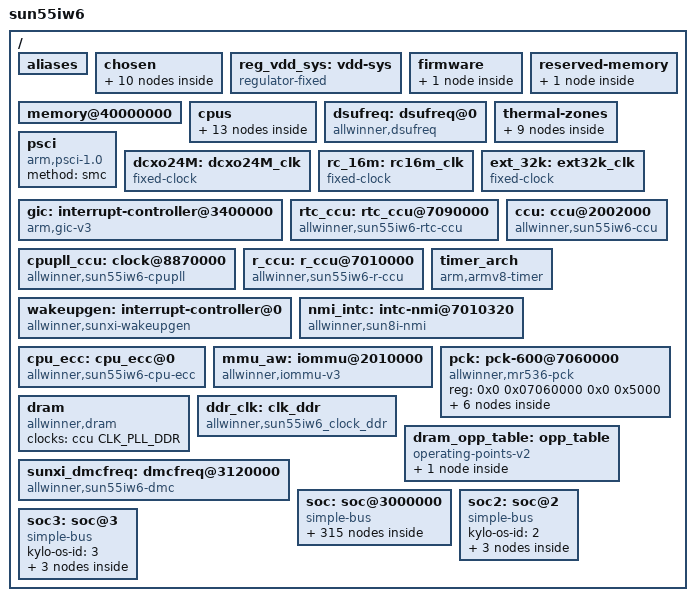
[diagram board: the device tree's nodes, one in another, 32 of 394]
// SPDX-License-Identifier: (GPL-2.0+ or MIT)
#include <dt-bindings/clock/sun55iw6-ccu.h>
#include <dt-bindings/clock/sun55iw6-rtc.h>
#include <dt-bindings/clock/sun55iw6-r-ccu.h>
#include <dt-bindings/gpio/gpio.h>
#include <dt-bindings/gpio/sun4i-gpio.h>
#include <dt-bindings/interrupt-controller/arm-gic.h>
#include <dt-bindings/reset/sun55iw6-ccu.h>
#include <dt-bindings/reset/sun55iw6-r-ccu.h>
#include <dt-bindings/power/mr536-power.h>
#include <dt-bindings/phy/phy.h>
#include <dt-bindings/thermal/thermal.h>
#include <dt-bindings/spi/sunxi-spi.h>
#include <dt-bindings/clock/sun55iw6-cpupll-ccu.h>
#include <dt-bindings/display/sunxi-lcd.h>
#include "sun55iw6p1-cpu-vf.dtsi"

/ {
	model = "sun55iw6";
	interrupt-parent = <&gic>;
	#address-cells = <2>;
	#size-cells = <2>;

	aliases {
		serial0 = &uart0;
		serial1 = &uart1;
		serial2 = &uart2;
		serial3 = &uart3;
		serial4 = &uart4;
		serial5 = &uart5;
		serial6 = &uart6;
		serial7 = &uart7;
		serial8 = &uart8;
		serial9 = &uart9;
		serial10 = &uart10;
		serial11 = &uart11;
		serial12 = &uart12;
		serial13 = &uart13;
		serial14 = &uart14;
		serial15 = &uart15;
		serial16 = &uart16;
		twi0 = &twi0;
		twi1 = &twi1;
		twi2 = &twi2;
		twi3 = &twi3;
		twi4 = &twi4;
		twi5 = &twi5;
		twi6 = &twi6;
		twi7 = &s_twi0;
		twi8 = &s_twi1;
		spi0 = &spi0;
		spi1 = &spi1;
		spi2 = &spi2;
		spi3 = &spi3;
		spi4 = &spi4;
		spi5 = &r_spi0;
		spif0 = &spif0;
		nand0 = &nand0;
		sunxi-mmc0 = &sdc0;
		sunxi-mmc2 = &sdc2;
		ir0 = &irrx0;
		ir1 = &irrx1;
		ir2 = &irrx2;
		ir3 = &irrx3;
		ir4 = &s_irrx;
		gpadc0 = &gpadc0;
		gpadc1 = &gpadc1;
		gpadc2 = &gpadc2;
		gpadc3 = &gpadc3;
		ethernet0 = &gmac0;
		ethernet1 = &gmac1;
		lbc = &lbc;
	};

	chosen {
		linux,initrd-start = <0x0 0x0>;
		linux,initrd-end = <0x0 0x0>;
		#address-cells = <0x2>;
		#size-cells = <0x1>;

		stdout-path = "/soc@3000000/uart@2500000";
		kylo-os-num = <3>;

		hyper {
			compatible = "kylo,kyper";
			reg = <0x0 0x60000000 0x08000000>;
		};

		dom1 {
			compatible = "xen,domain";
			#address-cells = <0x2>;
			#size-cells = <0x1>;
			memory = <0x0 0x140000>;
			xen,static-mem = <0x0 0x80000000 0x40000000>, <0x0 0x40000000 0x10000000>;
			cpu_ids = <&cpu0>,<&cpu1>;
			direct-map;
			kylo-os-type = <0>;  /* 0:linux  1:freeetos */

			module@0 {
				compatible = "multiboot,kernel", "multiboot,module";
				reg = <0x100 0x4008000 0xffffff>;           /* size update by uboot */
				reserve-bootargs;
				bootargs = " a=a ";
			};

			module@1 {
				compatible = "multiboot,ramdisk", "multiboot,module";
				reg = <0x0 0x41000000 0x4fffff>;  /* size update by uboot */
			};
		};

#if 1
		dom2 {
			compatible = "xen,domain";
			#address-cells = <0x2>;
			#size-cells = <0x1>;
			memory = <0x0 0x40000>;
			xen,static-mem = <0x0 0x50000000 0x10000000>;
			cpu_ids = <&cpu2>;
			/* vpl011; */
			direct-map;

			kylo-uart-args = "8,B,4,5,7";  /* uart8, PB4, PB5, 0111*/
			kylo-os-type = <0>;  /* 0:linux  1:freeetos */
			kylo-os-zone-name = "dom2-boot";

			module@0 {
				compatible = "multiboot,kernel", "multiboot,module";
				reg = <0x0 0x90000000 0x4000000>;      /* update by uboot, addr is boot.img base*/
				bootargs = " earlyprintk=sunxi-uart,0x02608000 root=/dev/mmcblk0p5 init=/init console=ttyAS8,115200 clk_ignore_unused";
			};

			module@1 {
				compatible = "multiboot,ramdisk", "multiboot,module";
				reg = <0x0 0x43000000 0xffffff>;       /* update by uboot */
			};

		};
#endif

#if 1
		dom3 {
			compatible = "xen,domain";
			#address-cells = <0x2>;
			#size-cells = <0x1>;
			memory = <0x0 0x40000>;
			xen,static-mem = <0x0 0x70000000 0x10000000>;
			cpu_ids = <&cpu3>;
			direct-map;
			kylo-uart-args = "2,B,0,1,2";  /* uart2, PB0, PB1, 0010*/
			kylo-os-type = <0>;  /* 0:linux  1:freeetos */
			kylo-os-zone-name = "dom2-boot";

			module@0 {
				compatible = "multiboot,kernel", "multiboot,module";
				reg = <0x0 0x98000000 0x4000000>;      /* update by uboot, addr is boot.img base */
				bootargs = " earlyprintk=sunxi-uart,0x02602000 root=/dev/mmcblk0p5 init=/init console=ttyAS2,115200 clk_ignore_unused";
			};

			module@1 {
				compatible = "multiboot,ramdisk", "multiboot,module";
				reg = <0x0 0x43000000 0xffffff>;       /* update by uboot */
			};
		};
#endif
	};


	reg_vdd_sys: vdd-sys {
		compatible = "regulator-fixed";
		regulator-name = "vdd_sys";
		regulator-min-microvolt = <900000>;
		regulator-max-microvolt = <900000>;
		regulator-boot-on;
		regulator-always-on;
	};

	firmware {
		optee {
			compatible = "linaro,optee-tz";
			method = "smc";
		};
	};

	reserved-memory {
		#address-cells = <2>;
		#size-cells = <2>;
		ranges;

		bl31 {
			reg = <0x0 0x48000000 0x0 0x01000000>;
		};
	};

	/* avoid panic when memory-node err(from uboot) */
	memory@40000000 {
		device_type = "memory";
		reg = <0x00000000 0x40000000 0x00000000 0x20000000>;
	};

	cpus {
		#address-cells = <2>;
		#size-cells = <0>;

		cpu0: cpu@0 {
			device_type = "cpu";
			compatible = "arm,cortex-a55";
			reg = <0x0 0x0>;
			enable-method = "psci";
			cpu-idle-states = <&CPU_SLEEP_0 &CLUSTER_SLEEP_0>;
			capacity-dmips-mhz = <1024>;
			clocks = <&cpupll_ccu CLK_PLL_CPU_L0>;
			operating-points-v2 = <&cluster_opp_table>;
			#cooling-cells = <2>;
			dynamic-power-coefficient = <286>;
		};

		cpu1: cpu@100 {
			device_type = "cpu";
			compatible = "arm,cortex-a55";
			reg = <0x0 0x100>;
			enable-method = "psci";
			cpu-idle-states = <&CPU_SLEEP_0 &CLUSTER_SLEEP_0>;
			capacity-dmips-mhz = <1024>;
			clocks = <&cpupll_ccu CLK_PLL_CPU_L0>;
			operating-points-v2 = <&cluster_opp_table>;
			#cooling-cells = <2>;
		};

		cpu2: cpu@200 {
			device_type = "cpu";
			compatible = "arm,cortex-a55";
			reg = <0x0 0x200>;
			enable-method = "psci";
			cpu-idle-states = <&CPU_SLEEP_0 &CLUSTER_SLEEP_0>;
			capacity-dmips-mhz = <1024>;
			clocks = <&cpupll_ccu CLK_PLL_CPU_L0>;
			operating-points-v2 = <&cluster_opp_table>;
			#cooling-cells = <2>;
		};

		cpu3: cpu@300 {
			device_type = "cpu";
			compatible = "arm,cortex-a55";
			reg = <0x0 0x300>;
			enable-method = "psci";
			cpu-idle-states = <&CPU_SLEEP_0 &CLUSTER_SLEEP_0>;
			capacity-dmips-mhz = <1024>;
			clocks = <&cpupll_ccu CLK_PLL_CPU_L0>;
			operating-points-v2 = <&cluster_opp_table>;
			#cooling-cells = <2>;
		};

		cpu-map {
			cluster0 {
				core0 {
					cpu = <&cpu0>;
				};
				core1 {
					cpu = <&cpu1>;
				};
				core2 {
					cpu = <&cpu2>;
				};
				core3 {
					cpu = <&cpu3>;
				};
			};
		};

		idle-states {
			entry-method = "arm,psci";

			CPU_SLEEP_0: cpu-sleep-0 {
				compatible = "arm,idle-state";
				arm,psci-suspend-param = <0x0010000>;
				entry-latency-us = <46>;
				exit-latency-us = <59>;
				min-residency-us = <3570>;
				local-timer-stop;
			};

			CLUSTER_SLEEP_0: cluster-sleep-0 {
				compatible = "arm,idle-state";
				arm,psci-suspend-param = <0x1010000>;
				entry-latency-us = <47>;
				exit-latency-us = <74>;
				min-residency-us = <5000>;
				local-timer-stop;
			};
		};
	};

	dsufreq: dsufreq@0 {
		compatible = "allwinner,dsufreq";
		reg = <0x0 0x08860000 0x0 0x1000>;
		clocks = <&cpupll_ccu CLK_PLL_DSU>;
		operating-points-v2 = <&dsu_opp_table>;
	};

	thermal-zones {
		cpu_thermal_zone: cpu_thermal_zone {
			polling-delay-passive = <100>;
			polling-delay = <1000>;
			thermal-sensors = <&ths 0>;
			sustainable-power = <1200>;

			cpu_trips: trips {
				cpu_threshold: trip-point@0 {
					temperature = <70000>;
					type = "passive";
					hysteresis = <0>;
				};
				cpu_target: trip-point@1 {
					temperature = <90000>;
					type = "passive";
					hysteresis = <0>;
				};
				cpu_crit: cpu_crit@0 {
					temperature = <110000>;
					type = "critical";
					hysteresis = <0>;
				};
			};

			cooling-maps {
				map0 {
					trip = <&cpu_target>;
					cooling-device = <&cpu0
					THERMAL_NO_LIMIT
					THERMAL_NO_LIMIT>;
					contribution = <1024>;
				};
			};
		};

		npu_thermal_zone {
			polling-delay-passive = <100>;
			polling-delay = <1000>;
			thermal-sensors = <&ths 1>;
		};

		ddr_thermal_zone {
			polling-delay-passive = <0>;
			polling-delay = <0>;
			thermal-sensors = <&ths 2>;
		};
	};


	psci {
		compatible = "arm,psci-1.0";
		method = "smc";
	};

	dcxo24M: dcxo24M_clk {
		#clock-cells = <0>;
		compatible = "fixed-clock";
		clock-frequency = <24000000>;
		clock-output-names = "dcxo24M";
		device-sharing;
	};

	rc_16m: rc16m_clk {
		#clock-cells = <0>;
		compatible = "fixed-clock";
		clock-frequency = <16000000>;
		clock-accuracy = <300000000>;
		clock-output-names = "rc-16m";
		device-sharing;
	};

	ext_32k: ext32k_clk {
		#clock-cells = <0>;
		compatible = "fixed-clock";
		clock-frequency = <32768>;
		clock-output-names = "ext-32k";
		device-sharing;
	};

	gic: interrupt-controller@3400000 {
		compatible = "arm,gic-v3";
		#interrupt-cells = <3>;
		#address-cells = <0>;
		ranges;
		interrupts = <GIC_PPI 9 0xf04>;  /* GIC Maintenence IRQ */
		interrupt-controller;
		reg = <0x0 0x03400000 0 0x10000>, /* GIC Dist */
		      <0x0 0x03460000 0 0xFF004>; /* GIC Re */
		interrupt-parent = <&gic>;
		phandle = <65000>;               /* use by hyper must need */
	};

	rtc_ccu: rtc_ccu@7090000 {
		compatible = "allwinner,sun55iw6-rtc-ccu";
		reg = <0x0 0x07090000 0x0 0x328>;
		#clock-cells = <1>;
		#reset-cells = <1>;
		device-sharing;
	};

	cpupll_ccu: clock@8870000 {
		compatible = "allwinner,sun55iw6-cpupll";
		reg = <0x0 0x08870000 0x0 0x78>;
		#clock-cells = <1>;
		#reset-cells = <1>;
		pll_step = <0x8>;
		pll_ssc = <0x3300>;
		device-sharing;
	};

	ccu: ccu@2002000 {
		compatible = "allwinner,sun55iw6-ccu";
		reg = <0x0 0x02002000 0x0 0x2000>;
		clocks = <&dcxo24M>, <&rtc_ccu CLK_OSC32K>, <&rc_16m>;
		clock-names = "hosc", "losc", "iosc";
		#clock-cells = <1>;
		#reset-cells = <1>;
		device-sharing;
	};

	r_ccu: r_ccu@7010000 {
		compatible = "allwinner,sun55iw6-r-ccu";
		reg = <0x0 0x07010000 0x0 0x230>;
		#clock-cells = <1>;
		#reset-cells = <1>;
		device-sharing;
	};

	wakeupgen: interrupt-controller@0 {
		compatible = "allwinner,sunxi-wakeupgen";
		interrupt-controller;
		#interrupt-cells = <3>;
		#address-cells = <0>;
		interrupt-parent = <&gic>;
	};

	timer_arch {
		compatible = "arm,armv8-timer";
		interrupts = <GIC_PPI 13 (GIC_CPU_MASK_SIMPLE(4) | IRQ_TYPE_LEVEL_LOW)>,
			   <GIC_PPI 14 (GIC_CPU_MASK_SIMPLE(4) | IRQ_TYPE_LEVEL_LOW)>,
			   <GIC_PPI 11 (GIC_CPU_MASK_SIMPLE(4) | IRQ_TYPE_LEVEL_LOW)>,
			   <GIC_PPI 10 (GIC_CPU_MASK_SIMPLE(4) | IRQ_TYPE_LEVEL_LOW)>;
		clock-frequency = <24000000>;
		interrupt-parent = <&gic>;
		arm,no-tick-in-suspend;
	};

	nmi_intc: intc-nmi@7010320 {
		compatible = "allwinner,sun8i-nmi";
		interrupt-parent = <&gic>;
		#interrupt-cells = <2>;
		#address-cells = <0>;
		interrupt-controller;
		reg = <0x0 0x07010320 0 0xc>;
		interrupts = <GIC_SPI 192 IRQ_TYPE_LEVEL_HIGH>;
	};

	cpu_ecc: cpu_ecc@0 {
		compatible = "allwinner,sun55iw6-cpu-ecc";
		interrupts = <GIC_SPI 242 IRQ_TYPE_LEVEL_HIGH>,
			<GIC_SPI 243 IRQ_TYPE_LEVEL_HIGH>,
			<GIC_SPI 244 IRQ_TYPE_LEVEL_HIGH>,
			<GIC_SPI 245 IRQ_TYPE_LEVEL_HIGH>,
			<GIC_SPI 246 IRQ_TYPE_LEVEL_HIGH>,
			<GIC_SPI 247 IRQ_TYPE_LEVEL_HIGH>,
			<GIC_SPI 248 IRQ_TYPE_LEVEL_HIGH>,
			<GIC_SPI 249 IRQ_TYPE_LEVEL_HIGH>,
			<GIC_SPI 250 IRQ_TYPE_LEVEL_HIGH>,
			<GIC_SPI 251 IRQ_TYPE_LEVEL_HIGH>;
		interrupt-names = "nerrirq0", "nerrirq1", "nerrirq2", "nerrirq3", "nerrirq4",
				"nfaultirq0", "nfaultirq1", "nfaultirq2", "nfaultirq3", "nfaultirq4";
	};

	mmu_aw: iommu@2010000 {
		compatible = "allwinner,iommu-v3";
		reg = <0x0 0x02010000 0x0 0x1000>;
		interrupts = <GIC_SPI 65 IRQ_TYPE_LEVEL_HIGH>;
		interrupt-names = "iommu-irq";
		clocks = <&ccu CLK_IOMMU>;
		clock-names = "iommu";
		/* clock-frequency = <24000000>; */
		#iommu-cells = <2>;
		version=<0x17>;
		tlb_prefetch = <0x3007f>;
		tlb_invalid_mode = <0x1>;
		ptw_invalid_mode = <0x1>;
		masters = "ISP", "CSI", "VE0", "RESERVED", "G2D",
			"DE", "E907", "DEBUG_MODE";
		valid_masters=<7>;
	};

	pck: pck-600@7060000 {
		compatible = "allwinner,mr536-pck", "syscon", "simple-mfd";
		reg = <0x0 0x07060000 0x0 0x5000>;

		pd: power-controller {
			compatible = "allwinner,mr536-pck-600";
			clocks = <&r_ccu CLK_R_PPU>;
			clock-names = "pck";
			#power-domain-cells = <1>;
			#address-cells = <1>;
			#size-cells = <0>;

			pd1_vi@MR536_PCK_VI {
				reg = <MR536_PCK_VI>;
			};
			pd1_ve@MR536_PCK_VE {
				reg = <MR536_PCK_VE>;
			};
			pd1_npu@MR536_PCK_NPU {
				reg = <MR536_PCK_NPU>;
			};
			pd1_serdes@MR536_PCK_SERDES {
				reg = <MR536_PCK_SERDES>;
			};
			pd1_vo@MR536_PCK_VO {
				reg = <MR536_PCK_VO>;
			};
		};
	};


	dram: dram {
		compatible = "allwinner,dram";
		clocks = <&ccu CLK_PLL_DDR>;
		clock-names = "pll_ddr";
	};

	ddr_clk: clk_ddr {
		compatible = "allwinner,sun55iw6_clock_ddr";
		reg = <0x0 0x02002000 0x0 0x1000>;
		clocks = <&ccu CLK_PLL_DDR>;
		clock-names = "pll_ddr";
		#clock-cells = <0>;
	};

	dram_opp_table: opp_table {
		compatible = "operating-points-v2";
		opp@150000000 {
			opp-hz = /bits/ 64 <150000000>;
			clock-latency-ns = <150000>;
			opp-microvolt = <900000>;
		};
	};

	sunxi_dmcfreq: dmcfreq@3120000 {
		compatible = "allwinner,sun55iw6-dmc", "syscon";
		reg = <0x0 0x03120000 0x0 0x11000>,
			  <0x0 0x02020000 0x0 0x4000>;
		interrupts = <GIC_SPI 121 IRQ_TYPE_LEVEL_HIGH>,
					 <GIC_SPI 229 IRQ_TYPE_LEVEL_HIGH>,
					 <GIC_SPI 233 IRQ_TYPE_LEVEL_HIGH>;
		clocks = <&ddr_clk>, <&ccu CLK_NSI>;
		clock-names = "dram", "bus";
		operating-points-v2 = <&dram_opp_table>;
		upthreshold = <60>;
		downdifferential = <20>;
		vddcore-supply = <&reg_vdd_sys>;
		normalvoltage = <900000>;
		boostvoltage = <900000>;
	};

	soc: soc@3000000 {
		compatible = "simple-bus";
		#address-cells = <2>;
		#size-cells = <2>;
		ranges;


		pio: pinctrl@3604000 {
			//#address-cells = <1>;
			//#size-cells = <0>;
			compatible = "allwinner,sun55iw6-pinctrl";
			reg = <0x0 0x03604000 0x0 0x600>;
			interrupts = <GIC_SPI 67 IRQ_TYPE_LEVEL_HIGH>,
				     <GIC_SPI 69 IRQ_TYPE_LEVEL_HIGH>,
				     <GIC_SPI 71 IRQ_TYPE_LEVEL_HIGH>,
				     <GIC_SPI 73 IRQ_TYPE_LEVEL_HIGH>,
				     <GIC_SPI 75 IRQ_TYPE_LEVEL_HIGH>,
				     <GIC_SPI 77 IRQ_TYPE_LEVEL_HIGH>,
				     <GIC_SPI 79 IRQ_TYPE_LEVEL_HIGH>,
				     <GIC_SPI 81 IRQ_TYPE_LEVEL_HIGH>,
				     <GIC_SPI 83 IRQ_TYPE_LEVEL_HIGH>,
				     <GIC_SPI 85 IRQ_TYPE_LEVEL_HIGH>,
				     <GIC_SPI 140 IRQ_TYPE_LEVEL_HIGH>;
			clocks = <&ccu CLK_APB1>, <&dcxo24M>, <&rtc_ccu CLK_OSC32K>;
			clock-names = "apb", "hosc", "losc";
			gpio-controller;
			#gpio-cells = <3>;
			interrupt-controller;
			#interrupt-cells = <3>;

			/* set appropriate driving strenth, other driving strenth signals are relatively poor, the cfg from shc  */
			sdc0_pins_a: sdc0@0 {
				pins = "PF2";
				function = "sdc0";
				drive-strength = <40>;
				bias-pull-up;
				power-source = <3300>;
			};

			sdc0_pins_b: sdc0@1 {
				pins = "PF2";
				function = "sdc0";
				drive-strength = <40>;
				bias-pull-up;
				power-source = <1800>;
			};

			sdc0_pins_c: sdc0@2 {
				pins = "PF0", "PF1", "PF2",
				"PF3", "PF4", "PF5";
				function = "gpio_in";
				power-source = <3300>;
			};

			/* TODO: add jtag pin */
			sdc0_pins_d: sdc0@3 {
				pins = "PF2", "PF4";
				function = "uart0";
				drive-strength = <10>;
				bias-pull-up;
				power-source = <3300>;
			};

			sdc0_pins_e: sdc0@4 {
				pins = "PF0", "PF1", "PF3",
						"PF5";
				function = "jtag";
				drive-strength = <10>;
				bias-pull-up;
				power-source = <3300>;
			};

			sdc0_pins_f: sdc0@5 {
				pins = "PF0", "PF1",
						"PF3", "PF4", "PF5";
				function = "sdc0";
				drive-strength = <30>;
				bias-pull-up;
				power-source = <3300>;
			};

			sdc0_pins_g: sdc0@6 {
				pins = "PF0", "PF1",
						"PF3", "PF4", "PF5";
				function = "sdc0";
				drive-strength = <30>;
				bias-pull-up;
				power-source = <1800>;
			};

			sdc1_pins_a: sdc1@0 {
				pins = "PG0";
				function = "sdc1";
				drive-strength = <40>;
				bias-pull-up;
			};

			sdc1_pins_b: sdc1@1 {
				pins = "PG0", "PG1", "PG2",
						"PG3", "PG4", "PG5";
				function = "gpio_in";
			};

			sdc1_pins_c: sdc1@2 {
				pins = "PG1", "PG2",
						"PG3", "PG4", "PG5";
				function = "sdc1";
				drive-strength = <20>;
				bias-pull-up;
			};

			sdc2_pins_a: sdc2@0 {
				pins = "PC1", "PC5";
				function = "sdc2";
				drive-strength = <40>;
				bias-pull-up;
			};

			sdc2_pins_b: sdc2@1 {
				pins = "PC0", "PC1", "PC5", "PC6",
						"PC8", "PC9", "PC10", "PC11",
						"PC13", "PC14", "PC15", "PC16";
				function = "gpio_in";
			};

			sdc2_pins_c: sdc2@2 {
				pins = "PC0";
				function = "sdc2";
				drive-strength = <40>;
				bias-pull-down;
			};

			sdc2_pins_d: sdc2@3 {
				pins = "PC6",
						"PC8", "PC9", "PC10", "PC11",
						"PC13", "PC14", "PC15", "PC16";
				function = "sdc2";
				drive-strength = <20>;
				bias-pull-up;
			};

			test_pins_a: test_pins@0 {
				pins = "PB0", "PB1";
				function = "test";
				drive-strength = <10>;
				bias-pull-up;
			};

			test_pins_b: test_pins@1 {
				pins = "PB0", "PB1";
				function = "gpio_in";
			};

			dsi0_4lane_pins_a: dsi0_4lane@0 {
				pins = "PD0", "PD1", "PD2", "PD3", "PD4", "PD5", "PD6", "PD7", "PD8", "PD9";
				function = "dsi";
				drive-strength = <30>;
				bias-disable;
			};

			dsi0_4lane_pins_b: dsi0_4lane@1 {
				pins = "PD0", "PD1", "PD2", "PD3", "PD4", "PD5", "PD6", "PD7", "PD8", "PD9";
				function = "io_disabled";
				bias-disable;
			};

			lvds0_pins_a: lvds0@0 {
				pins = "PD0", "PD1", "PD2", "PD3", "PD4", "PD5", "PD6", "PD7", "PD8", "PD9";
				function = "lvds0";
				drive-strength = <30>;
			};

			lvds0_pins_b: lvds0@1 {
				pins = "PD0", "PD1", "PD2", "PD3", "PD4", "PD5", "PD6", "PD7", "PD8", "PD9";
				function = "gpio_in";
			};

			lvds1_pins_a: lvds1@0 {
				pins = "PD10", "PD11", "PD12", "PD13", "PD14", "PD15", "PD16", "PD17", "PD18", "PD19";
				function = "lvds1";
				drive-strength = <30>;
			};

			lvds1_pins_b: lvds1@1 {
				pins = "PD10", "PD11", "PD12", "PD13", "PD14", "PD15", "PD16", "PD17", "PD18", "PD19";
				function = "gpio_in";
			};

			rgb0_24pins_a: rgb0@0 {
				pins = "PH8", "PH9", "PD0", "PD1", "PD2", "PD3", "PD4", "PD5", "PH10", "PH11", "PD6", "PD7", "PD8", "PD9", \
					"PD10", "PD11", "PH12", "PH13", "PD12", "PD13", "PD14", "PD15", "PD16", "PD17", "PD18", "PD19", \
					"PD20", "PD21";
				function = "lcd";
				drive-strength = <30>;
			};

			rgb0_24pins_b: rgb0@1 {
				pins = "PH8", "PH9", "PD0", "PD1", "PD2", "PD3", "PD4", "PD5", "PH10", "PH11", "PD6", "PD7", "PD8", "PD9", \
					"PD10", "PD11", "PH12", "PH13", "PD12", "PD13", "PD14", "PD15", "PD16", "PD17", "PD18", "PD19", \
					"PD20", "PD21";
				function = "gpio_in";
			};

			csi_mclk0_pins_a: csi_mclk0@0 {
				pins = "PE0";
				function = "mcsi0_mclk";
				drive-strength = <10>;
			};

			csi_mclk0_pins_b: csi_mclk0@1 {
				pins = "PE0";
				function = "gpio_in";
			};

			csi_mclk1_pins_a: csi_mclk1@0 {
				pins = "PE5";
				function = "mcsi1_mclk";
				drive-strength = <10>;
			};

			csi_mclk1_pins_b: csi_mclk1@1 {
				pins = "PE5";
				function = "gpio_in";
			};

			csi_mclk2_pins_a: csi_mclk2@0 {
				pins = "PE15";
				function = "mcsi2_mclk";
				drive-strength = <10>;
			};

			csi_mclk2_pins_b: csi_mclk2@1 {
				pins = "PE15";
				function = "gpio_in";
			};

			csi_mclk3_pins_a: csi_mclk3@0 {
				pins = "PE10";
				function = "mcsi3_mclk";
				drive-strength = <10>;
			};

			csi_mclk3_pins_b: csi_mclk3@1 {
				pins = "PE10";
				function = "gpio_in";
			};

			ncsi_bt656_pins_a: ncsi_BT656@0 {
				pins = "PK20", "PK22", "PK23",
				"PK4", "PK5", "PK6", "PK7",
				"PK8", "PK9", "PK10", "PK11";
				function = "ncsi";
				drive-strength = <10>;
			};

			ncsi_bt656_pins_b: ncsi_BT656@1 {
				pins = "PK20", "PK22", "PK23",
				"PK4", "PK5", "PK6", "PK7",
				"PK8", "PK9", "PK10", "PK11";
				function = "gpio_in";
			};

			ncsi_bt1120_pins_a: ncsi_BT1120@0 {
				pins = "PK20", "PK22", "PK23",
				"PK4", "PK5", "PK6", "PK7",
				"PK8", "PK9", "PK10", "PK11",
				"PK12", "PK13", "PK14", "PK15",
				"PK16", "PK17", "PK18", "PK19";
				function = "ncsi";
				drive-strength = <10>;
			};

			ncsi_bt1120_pins_b: ncsi_BT1120@1 {
				pins = "PK20", "PK22", "PK23",
				"PK4", "PK5", "PK6", "PK7",
				"PK8", "PK9", "PK10", "PK11",
				"PK12", "PK13", "PK14", "PK15",
				"PK16", "PK17", "PK18", "PK19";
				function = "gpio_in";
			};

			mipia_pins_a: mipia@0 {
				pins = "PK0", "PK1", "PK2",
					"PK3", "PK4", "PK5";
				function = "mcsia";
				drive-strength = <10>;

			};

			mipia_pins_b: mipia@1 {
				pins = "PK0", "PK1", "PK2",
					"PK3", "PK4", "PK5";
				function = "gpio_in";
			};

			mipib_pins_a: mipib@0 {
				pins = "PK6", "PK7", "PK8",
					"PK9", "PK10", "PK11";
				function = "mcsib";
				drive-strength = <10>;
			};

			mipib_pins_b: mipib@1 {
				pins = "PK6", "PK7", "PK8",
					"PK9", "PK10", "PK11";
				function = "gpio_in";

			};

			mipib_4lane_pins_a: mipib_4lane@0 {
				pins = "PK6", "PK7", "PK8",
					"PK9", "PK10", "PK11";
				function = "mcsib";
				drive-strength = <10>;
			};

			mipib_4lane_pins_b: mipib_4lane@1 {
				pins = "PK6", "PK7", "PK8",
					"PK9", "PK10", "PK11";
				function = "gpio_in";
			};

			mipic_pins_a: mipic@0 {
				pins = "PK12", "PK13", "PK14",
					"PK15", "PK16", "PK17";
				function = "mcsic";
				drive-strength = <10>;

			};

			mipic_pins_b: mipic@1 {
				pins = "PK12", "PK13", "PK14",
					"PK15", "PK16", "PK17";
				function = "gpio_in";
			};

			mipid_pins_a: mipid@0 {
				pins = "PK18", "PK19", "PK20",
					"PK21", "PK22", "PK23";
				function = "mcsid";
				drive-strength = <10>;
			};

			mipid_pins_b: mipid@1 {
				pins = "PK18", "PK19", "PK20",
					"PK21", "PK22", "PK23";
				function = "gpio_in";

			};

			mipid_4lane_pins_a: mipid_4lane@0 {
				pins = "PK18", "PK19", "PK20",
					"PK21", "PK22", "PK23";
				function = "mcsid";
				drive-strength = <10>;
			};

			mipid_4lane_pins_b: mipid_4lane@1 {
				pins = "PK18", "PK19", "PK20",
					"PK21", "PK22", "PK23";
				function = "gpio_in";
			};
		};

		r_pio: pinctrl@7096000 {
			#address-cells = <1>;
			compatible = "allwinner,sun55iw6-r-pinctrl";
			reg = <0x0 0x07096000 0x0 0x800>;
			interrupts = <GIC_SPI 202 IRQ_TYPE_LEVEL_HIGH>, /* GPIOL */
				     <GIC_SPI 204 IRQ_TYPE_LEVEL_HIGH>;     /* GPIOM */
			clocks = <&ccu CLK_R_APBS1>, <&dcxo24M>, <&rtc_ccu CLK_OSC32K>;
			clock-names = "apb", "hosc", "losc";
			gpio-controller;
			#gpio-cells = <3>;
			interrupt-controller;
			#interrupt-cells = <3>;
		};

		pinctrl_test: pinctrl_test@2000000 {
		      reg = <0x0 0x0 0x0 0x0>;
		      compatible = "allwinner,sunxi-pinctrl-test";
		      device_type = "pinctrl-test";
		      pinctrl-0 = <&test_pins_a>;
		      pinctrl-1 = <&test_pins_b>;
		      pinctrl-names = "default", "sleep";
		      test-gpios = <&pio PB 4 GPIO_ACTIVE_LOW>;
		      suspend-gpios = <&pio PB 5 GPIO_ACTIVE_LOW>;
		      wakeup-source;
		      interrupt-parent = <&pio>;
		      interrupts = <PB 6 IRQ_TYPE_LEVEL_HIGH>;
		};

		ths: ths@2086000 {
			compatible = "allwinner,sun55iw6p1-ths";
			reg = <0x0 0x02086000 0x0 0x400>;
			clocks = <&ccu CLK_THS>,<&ccu CLK_GPADC2>;
			clock-names = "bus","gpadc";
			resets = <&ccu RST_BUS_TH>;
			#thermal-sensor-cells = <1>;
		};

		soc_timer0: timer@3008000 {
			compatible = "allwinner,hstimer-v100";
			device_type = "soc_timer";
			reg = <0x0 0x03008000 0x0 0x400>;
			interrupt-parent = <&gic>;
			interrupts = <GIC_SPI 55 IRQ_TYPE_LEVEL_HIGH>;
			clock-names = "parent", "bus", "timer0-mod", "timer1-mod";
			clocks = <&dcxo24M>, <&ccu CLK_BUS_TIMER>, <&ccu CLK_TIMER0>, <&ccu CLK_TIMER1>;
			resets = <&ccu RST_BUS_TIME>;
		};

		arm_pmu {
			compatible = "arm,armv8-pmuv3";
			interrupt-parent = <&gic>;
			interrupts = <GIC_PPI 7 IRQ_TYPE_LEVEL_HIGH>;
		};

		cryptoengine: ce@3040000 {
			compatible = "allwinner,sunxi-ce";
			device_name = "ce";
			reg = <0x0 0x03040000 0x0 0x800>, /* non-secure space */
				<0x0 0x03040800 0x0 0x800>; /* secure space */
			interrupts = <GIC_SPI 52 IRQ_TYPE_EDGE_RISING>, /*non-secure*/
				<GIC_SPI 53 IRQ_TYPE_EDGE_RISING>; /* secure*/
			clock-frequency = <400000000>; /* 400MHz */
			clocks = <&ccu CLK_BUS_CE>, <&ccu CLK_CE>, <&ccu CLK_MBUS_CE_GATE>,
				 <&ccu CLK_PLL_PERI0_400M>, <&ccu CLK_CE_SYS>;
			clock-names = "bus_ce", "ce_clk", "mbus_ce", "clk_src", "ce_sys_clk";
			resets = <&ccu RST_BUS_CE>;
			status = "disabled";
		};

		rtc: rtc@7090000 {
			compatible = "allwinner,rtc-v201";
			device_type = "rtc";
			wakeup-source;
			reg = <0x0 0x07090000 0x0 0x320>;
			interrupts = <GIC_SPI 200 IRQ_TYPE_LEVEL_HIGH>;
			clocks = <&r_ccu CLK_RTC>, <&rtc_ccu CLK_RTC_1K>, <&rtc_ccu CLK_RTC_SPI>;
			clock-names = "r-ahb-rtc", "rtc-1k", "rtc-spi";
			resets = <&r_ccu RST_BUS_RTC>;
			gpr_cur_pos = <6>;
			gpr_bootcount_pos = <7>;
		};

		dump_reg: dump_reg@40000 {
			compatible = "allwinner,sunxi-dump-reg";
			reg = <0x0 0x00040000 0x0 0x0004>;
		};

		wdt: watchdog@2050000 {
			compatible = "allwinner,wdt-v103";
			reg = <0x0 0x02050000 0x0 0x20>;
			interrupts = <GIC_SPI 63 IRQ_TYPE_LEVEL_HIGH>;
		};

		uart0: uart@2600000 {
			compatible = "allwinner,uart-v100";
			reg = <0x0 0x02600000 0x0 0x400>;
			interrupts = <GIC_SPI 2 IRQ_TYPE_LEVEL_HIGH>;
			sunxi,uart-fifosize = <64>;
			clocks = <&ccu CLK_BUS_UART0>;
			resets = <&ccu RST_BUS_UART0>;
			uart0_port = <0>;
			uart0_type = <2>;
			status = "disabled";
		};

		uart1: uart@2601000 {
			compatible = "allwinner,uart-v100";
			device_type = "uart1";
			reg = <0x0 0x02601000 0x0 0x400>;
			interrupts = <GIC_SPI 3 IRQ_TYPE_LEVEL_HIGH>;
			sunxi,uart-fifosize = <128>;
			clocks = <&ccu CLK_BUS_UART1>;
			resets = <&ccu RST_BUS_UART1>;
			uart1_port = <1>;
			uart1_type = <4>;
			//dmas = <&dma0 15>,<&dma0 15>;
			//dma-names = "tx","rx";
			status = "disabled";
		};


		uart3: uart@2603000 {
			compatible = "allwinner,uart-v100";
			device_type = "uart3";
			reg = <0x0 0x02603000 0x0 0x400>;
			interrupts = <GIC_SPI 5 IRQ_TYPE_LEVEL_HIGH>;
			sunxi,uart-fifosize = <128>;
			clocks = <&ccu CLK_BUS_UART3>;
			resets = <&ccu RST_BUS_UART3>;
			uart3_port = <3>;
			uart3_type = <4>;
			//dmas = <&dma0 17>,<&dma0 17>;
			//dma-names = "tx","rx";
			status = "disabled";
		};

		uart4: uart@2604000 {
			compatible = "allwinner,uart-v100";
			device_type = "uart4";
			reg = <0x0 0x02604000 0x0 0x400>;
			interrupts = <GIC_SPI 6 IRQ_TYPE_LEVEL_HIGH>;
			sunxi,uart-fifosize = <128>;
			clocks = <&ccu CLK_BUS_UART4>;
			resets = <&ccu RST_BUS_UART4>;
			uart4_port = <4>;
			uart4_type = <4>;
			//dmas = <&dma0 18>,<&dma0 18>;
			//dma-names = "tx","rx";
			status = "disabled";
		};

		uart5: uart@2605000 {
			compatible = "allwinner,uart-v100";
			device_type = "uart5";
			reg = <0x0 0x02605000 0x0 0x400>;
			interrupts = <GIC_SPI 7 IRQ_TYPE_LEVEL_HIGH>;
			sunxi,uart-fifosize = <128>;
			clocks = <&ccu CLK_BUS_UART5>;
			resets = <&ccu RST_BUS_UART5>;
			uart5_port = <5>;
			uart5_type = <4>;
			//dmas = <&dma0 19>,<&dma0 19>;
			//dma-names = "tx","rx";
			status = "disabled";
		};

		uart6: uart@2606000 {
			compatible = "allwinner,uart-v100";
			device_type = "uart6";
			reg = <0x0 0x02606000 0x0 0x400>;
			interrupts = <GIC_SPI 8 IRQ_TYPE_LEVEL_HIGH>;
			sunxi,uart-fifosize = <128>;
			clocks = <&ccu CLK_BUS_UART6>;
			resets = <&ccu RST_BUS_UART6>;
			uart6_port = <6>;
			uart6_type = <4>;
			//dmas = <&dma0 20>,<&dma0 20>;
			//dma-names = "tx","rx";
			status = "disabled";
		};

		uart7: uart@2607000 {
			compatible = "allwinner,uart-v100";
			device_type = "uart7";
			reg = <0x0 0x02607000 0x0 0x400>;
			interrupts = <GIC_SPI 9 IRQ_TYPE_LEVEL_HIGH>;
			sunxi,uart-fifosize = <128>;
			clocks = <&ccu CLK_BUS_UART7>;
			resets = <&ccu RST_BUS_UART7>;
			uart7_port = <7>;
			uart7_type = <4>;
			//dmas = <&dma0 21>,<&dma0 21>;
			//dma-names = "tx","rx";
			status = "disabled";
		};

		uart9: uart@2609000 {
			compatible = "allwinner,uart-v100";
			device_type = "uart9";
			reg = <0x0 0x02609000 0x0 0x400>;
			interrupts = <GIC_SPI 149 IRQ_TYPE_LEVEL_HIGH>;
			sunxi,uart-fifosize = <64>;
			clocks = <&ccu CLK_BUS_UART9>;
			resets = <&ccu RST_BUS_UART9>;
			uart9_port = <9>;
			uart9_type = <4>;
			//dmas = <&dma0 56>,<&dma0 56>;
			//dma-names = "tx","rx";
			status = "disabled";
		};

		uart10: uart@260a000 {
			compatible = "allwinner,uart-v100";
			device_type = "uart10";
			reg = <0x0 0x0260a000 0x0 0x400>;
			interrupts = <GIC_SPI 150 IRQ_TYPE_LEVEL_HIGH>;
			sunxi,uart-fifosize = <64>;
			clocks = <&ccu CLK_BUS_UART10>;
			resets = <&ccu RST_BUS_UART10>;
			uart10_port = <10>;
			uart10_type = <4>;
			//dmas = <&dma0 57>,<&dma0 57>;
			//dma-names = "tx","rx";
			status = "disabled";
		};

		uart11: uart@260b000 {
			compatible = "allwinner,uart-v100";
			device_type = "uart11";
			reg = <0x0 0x0260b000 0x0 0x400>;
			interrupts = <GIC_SPI 151 IRQ_TYPE_LEVEL_HIGH>;
			sunxi,uart-fifosize = <64>;
			clocks = <&ccu CLK_BUS_UART11>;
			resets = <&ccu RST_BUS_UART11>;
			uart11_port = <11>;
			uart11_type = <4>;
			//dmas = <&dma0 58>,<&dma0 58>;
			//dma-names = "tx","rx";
			status = "disabled";
		};

		uart12: uart@260c000 {
			compatible = "allwinner,uart-v100";
			device_type = "uart12";
			reg = <0x0 0x0260c000 0x0 0x400>;
			interrupts = <GIC_SPI 152 IRQ_TYPE_LEVEL_HIGH>;
			sunxi,uart-fifosize = <64>;
			clocks = <&ccu CLK_BUS_UART12>;
			resets = <&ccu RST_BUS_UART12>;
			uart12_port = <12>;
			uart12_type = <4>;
			//dmas = <&dma0 59>,<&dma0 59>;
			//dma-names = "tx","rx";
			status = "disabled";
		};

		uart13: uart@260d000 {
			compatible = "allwinner,uart-v100";
			device_type = "uart13";
			reg = <0x0 0x0260d000 0x0 0x400>;
			interrupts = <GIC_SPI 153 IRQ_TYPE_LEVEL_HIGH>;
			sunxi,uart-fifosize = <64>;
			clocks = <&ccu CLK_BUS_UART13>;
			resets = <&ccu RST_BUS_UART13>;
			uart13_port = <13>;
			uart13_type = <4>;
			//dmas = <&dma0 60>,<&dma0 60>;
			//dma-names = "tx","rx";
			status = "disabled";
		};

		uart14: uart@260e000 {
			compatible = "allwinner,uart-v100";
			device_type = "uart14";
			reg = <0x0 0x0260e000 0x0 0x400>;
			interrupts = <GIC_SPI 154 IRQ_TYPE_LEVEL_HIGH>;
			sunxi,uart-fifosize = <64>;
			clocks = <&ccu CLK_BUS_UART14>;
			resets = <&ccu RST_BUS_UART14>;
			uart14_port = <14>;
			uart14_type = <4>;
			//dmas = <&dma0 61>,<&dma0 61>;
			//dma-names = "tx","rx";
			status = "disabled";
		};

		uart15: uart@7080000{
			compatible = "allwinner,uart-v100";
			device_type = "uart15";
			reg = <0x0 0x07080000 0x0 0x400>;
			interrupts = <GIC_SPI 205 IRQ_TYPE_LEVEL_HIGH>;
			sunxi,uart-fifosize = <64>;
			clocks = <&r_ccu CLK_R_UART0>;
			resets = <&r_ccu RST_BUS_R_UART0>;
			uart15_port = <15>;
			uart15_type = <4>;
			//dmas = <&dma0 51>,<&dma0 51>;
			//dma-names = "tx","rx";
			status = "disabled";
		};

		uart16: uart@7081000{
			compatible = "allwinner,uart-v100";
			device_type = "uart16";
			reg = <0x0 0x07081000 0x0 0x400>;
			interrupts = <GIC_SPI 206 IRQ_TYPE_LEVEL_HIGH>;
			sunxi,uart-fifosize = <128>;
			clocks = <&r_ccu CLK_R_UART1>;
			resets = <&r_ccu RST_BUS_R_UART1>;
			uart16_port = <16>;
			uart16_type = <4>;
			//dmas = <&dma0 52>,<&dma0 52>;
			//dma-names = "tx","rx";
			status = "disabled";
		};

		rtp: rtp@208c000 {
			compatible = "allwinner,sunxi-rtp-v101";
			reg = <0x0 0x0208c000 0x0 0x400>;
			clocks = <&ccu CLK_TPADC>, <&ccu CLK_TPADC_24M>;
			clock-names = "mod", "bus";
			clock-frequency = <1000000>;
			resets = <&ccu RST_BUS_TPADC>;
			interrupts = <GIC_SPI 159 IRQ_TYPE_LEVEL_HIGH>;
			status = "disabled";
		};

		sdc2: sdmmc@4022000 {
			compatible = "allwinner,sunxi-mmc-v4p6x";
			device_type = "sdc2";
			reg = <0x0 0x04022000 0x0 0x1000>;
			interrupts = <GIC_SPI 42 IRQ_TYPE_LEVEL_HIGH>;
			clocks = <&dcxo24M>,
					<&ccu CLK_PLL_PERI1_800M>,
					<&ccu CLK_PLL_PERI1_600M>,
					<&ccu CLK_SMHC2>,
					<&ccu CLK_BUS_SMHC2>;
			clock-names = "osc24m","pll_periph","pll_periph_2","mmc","ahb";
			resets = <&ccu RST_BUS_SMHC2>;
			reset-names = "rst";
			pinctrl-names = "default","sleep";
			pinctrl-0 = <&sdc2_pins_a &sdc2_pins_c &sdc2_pins_d>;
			pinctrl-1 = <&sdc2_pins_b>;
			bus-width = <8>;
			req-page-count = <2>;
			cap-mmc-highspeed;
			cap-cmd23;
			mmc-cache-ctrl;
			non-removable;
			/*max-frequency = <200000000>;*/
			max-frequency = <50000000>;
			cap-erase;
			mmc-high-capacity-erase-size;
			no-sdio;
			no-sd;
			/*-- speed mode --*/
			/*sm0: DS26_SDR12*/
			/*sm1: HSSDR52_SDR25*/
			/*sm2: HSDDR52_DDR50*/
			/*sm3: HS200_SDR104*/
			/*sm4: HS400*/
			/*-- frequency point --*/
			/*f0: CLK_400K*/
			/*f1: CLK_25M*/
			/*f2: CLK_50M*/
			/*f3: CLK_100M*/
			/*f4: CLK_150M*/
			/*f5: CLK_200M*/
			ctl-spec-caps = <0x328>;
			sdc_tm4_sm0_freq0 = <0>;
			sdc_tm4_sm0_freq1 = <0>;
			sdc_tm4_sm1_freq0 = <0x00000000>;
			sdc_tm4_sm1_freq1 = <0>;
			sdc_tm4_sm2_freq0 = <0x00000000>;
			sdc_tm4_sm2_freq1 = <0>;
			sdc_tm4_sm3_freq0 = <0x05000000>;
			sdc_tm4_sm3_freq1 = <0x00000005>;
			sdc_tm4_sm4_freq0 = <0x00050000>;
			sdc_tm4_sm4_freq1 = <0x00000004>;
			sdc_tm4_sm4_freq0_cmd = <0>;
			sdc_tm4_sm4_freq1_cmd = <0>;

			/*vmmc-supply = <&reg_3p3v>;*/
			/*vqmc-supply = <&reg_3p3v>;*/
			/*vdmc-supply = <&reg_3p3v>;*/
			/*vmmc = "vcc-card";*/
			/*vqmc = "";*/
			/*vdmc = "";*/
			/*sunxi-power-save-mode;*/
			status = "disabled";
		};

		irrx0: irrx@2081000 {
			compatible = "allwinner,irrx";
			reg = <0x0 0x02081000 0x0 0x400>;
			interrupts = <GIC_SPI 27 IRQ_TYPE_LEVEL_HIGH>;
			clocks = <&ccu CLK_BUS_IRRX0>, <&dcxo24M>, <&ccu CLK_IRRX0>;
			clock-names = "bus", "pclk", "mclk";
			resets = <&ccu RST_BUS_IRRX0>;
			status = "disabled";
		};

		irrx1: irrx@2082000 {
			compatible = "allwinner,irrx";
			reg = <0x0 0x02082000 0x0 0x400>;
			interrupts = <GIC_SPI 117 IRQ_TYPE_LEVEL_HIGH>;
			clocks = <&ccu CLK_BUS_IRRX1>, <&dcxo24M>, <&ccu CLK_IRRX1>;
			clock-names = "bus", "pclk", "mclk";
			resets = <&ccu RST_BUS_IRRX1>;
			status = "disabled";
		};

		irrx2: irrx@2083000 {
			compatible = "allwinner,irrx";
			reg = <0x0 0x02083000 0x0 0x400>;
			interrupts = <GIC_SPI 118 IRQ_TYPE_LEVEL_HIGH>;
			clocks = <&ccu CLK_BUS_IRRX2>, <&dcxo24M>, <&ccu CLK_IRRX2>;
			clock-names = "bus", "pclk", "mclk";
			resets = <&ccu RST_BUS_IRRX2>;
			status = "disabled";
		};

		irrx3: irrx@2084000 {
			compatible = "allwinner,irrx";
			reg = <0x0 0x02084000 0x0 0x400>;
			interrupts = <GIC_SPI 119 IRQ_TYPE_LEVEL_HIGH>;
			clocks = <&ccu CLK_BUS_IRRX3>, <&dcxo24M>, <&ccu CLK_IRRX3>;
			clock-names = "bus", "pclk", "mclk";
			resets = <&ccu RST_BUS_IRRX3>;
			status = "disabled";
		};

		s_irrx: irrx@7040000 {
			compatible = "allwinner,irrx";
			reg = <0x0 0x07040000 0x0 0x400>;
			interrupts = <GIC_SPI 210 IRQ_TYPE_LEVEL_HIGH>;
			clocks = <&r_ccu CLK_R_BUS_IRRX>, <&dcxo24M>, <&r_ccu CLK_R_IRRX>;
			clock-names = "bus", "pclk", "mclk";
			resets = <&r_ccu RST_BUS_R_IRRX>;
			status = "disabled";
		};

		irtx0: irtx@2080000 {
			compatible = "allwinner,irtx";
			reg = <0x0 0x02080000 0x0 0x400>;
			interrupts = <GIC_SPI 26 IRQ_TYPE_LEVEL_HIGH>;
			clocks = <&ccu CLK_BUS_IRTX>, <&dcxo24M>, <&ccu CLK_IRTX>;
			clock-names = "bus", "pclk", "mclk";
			resets = <&ccu RST_BUS_IRTX>;
			status = "disabled";
		};

		ledc: ledc@2085000 {
			#address-cells = <1>;
			#size-cells = <0>;
			compatible = "allwinner,sunxi-leds";
			reg = <0x0 0x02085000 0x0 0x400>;
			interrupts = <GIC_SPI 28 IRQ_TYPE_LEVEL_HIGH>;
			clocks = <&ccu CLK_LEDC>, <&ccu CLK_BUS_LEDC>;
			clock-names = "clk_ledc", "clk_cpuapb";
			resets = <&ccu RST_BUS_LEDC>;
			reset-names = "ledc_reset";
			dmas = <&dma0 42>;
			dma-names = "tx";
			status = "disabled";
		};

		lradc: lradc@208b000 {
			compatible = "allwinner,keyboard_1350mv";
			reg = <0x0 0x0208b000 0x0 0x400>;
			interrupts = <GIC_SPI 66 IRQ_TYPE_LEVEL_HIGH>;
			clocks = <&ccu CLK_LRADC>;
			resets = <&ccu RST_BUS_LRADC>;
			status = "disabled";
		};

		npu: npu@1900000 {
			compatible = "allwinner,npu";
			reg = <0x0 0x01900000 0x0 0x1000>;
			device_type = "npu";
			dev_name = "npu";
			interrupts = <GIC_SPI 116 IRQ_TYPE_LEVEL_HIGH>;
			interrupt-names = "npu";
			clocks = <&ccu CLK_NPU>, <&ccu CLK_PLL_NPU_4X>, <&ccu CLK_NPU_TZMA>, <&ccu CLK_BUS_NPU>;
			clock-names = "clk_npu", "clk_parent", "clk_tzma", "clk_bus";
			operating-points-v2 = <&npu_opp_table>;
			resets = <&ccu RST_BUS_NPU_CORE>, <&ccu RST_BUS_NPU_AXI>, <&ccu RST_BUS_NPU_AHB>;
			reset-names = "npu_rst", "npu_axi_rst", "npu_ahb_rst";
			/*
			 * power-domains = <&pd Ti533_PD_NPU>;
			 */
			npu-vf = <696>;
			npu-regulator = <1>;
			status = "disabled";
		};

		sunxi_drm: sunxi-drm {
			compatible = "allwinner,sunxi-drm";
			status = "disabled";
		};

		de: de@5000000 {
			compatible = "allwinner,display-engine-v210";
			iommus = <&mmu_aw 5 1>;
			power-domains = <&pd MR536_PCK_VO>;
			reg = <0x0 0x5000000 0x0 0x400000>;
			interrupts = <GIC_SPI 87 IRQ_TYPE_LEVEL_HIGH>;
			clocks = <&ccu CLK_DE>,
				 <&ccu CLK_DE0>,
				 <&ccu CLK_AHB_VID_OUT_GATE>,
				 <&ccu CLK_MBUS_VO_SYS_GATE>;
			clock-names = "clk_de",
				      "clk_bus_de",
				      "ahb_vid_out",
				      "mbus_vo_sys";
			resets = <&ccu RST_BUS_DE0>;
			reset-names = "rst_bus_de";
			assigned-clocks = <&ccu CLK_DE>;
			assigned-clock-parents = <&ccu CLK_PLL_PERI0_600M>;
			assigned-clock-rates = <300000000>;
			status = "disabled";
			ports {
				disp0: port@0 {
					disp0_out_tcon0: endpoint@0 {
						remote-endpoint = <&tcon0_in_disp0>;
					};
				};
			};
		};

		vo0: vo0@5500000 {
			compatible = "allwinner,tcon-top0";
			reg = <0x0 0x05500000 0x0 0xfff>;
			power-domains = <&pd MR536_PCK_VO>;
			clocks = <&ccu CLK_DPSS>;
			clock-names = "clk_bus_dpss_top";
			resets = <&ccu RST_BUS_DP>,
				 <&ccu RST_BUS_VIDEO_OUT0>;
			reset-names = "rst_bus_dpss_top",
				      "rst_bus_reg";
			status = "disabled";
		};

		lcd0: tcon0@5501000 {
			compatible = "allwinner,tcon-lcd";
			reg = <0x0 0x05501000 0x0 0x1000>;
			interrupts = <GIC_SPI 90 IRQ_TYPE_LEVEL_HIGH>;
			clocks = <&ccu CLK_VO0_TCONLCD0>,
				<&ccu CLK_BUS_VO0_TCONLCD0>,
				 <&ccu CLK_AHB_VID_OUT_GATE>,
				 <&ccu CLK_MBUS_VO_SYS_GATE>;
			clock-names = "clk_tcon",
					"clk_bus_tcon",
					"ahb_vid_out",
					"mbus_vo_sys";
			assigned-clocks = <&ccu CLK_VO0_TCONLCD0>;
			assigned-clock-parents = <&ccu CLK_PLL_VIDEO0_4X>;
			resets = <&ccu RST_BUS_VO0_TCONLCD0>;
			reset-names = "rst_bus_tcon";
			top = <&vo0>;
			status = "disabled";
			ports {
				#address-cells = <1>;
				#size-cells = <0>;
				tcon0_in: port@0 {
					reg = <0>;
					tcon0_in_disp0: endpoint@0 {
						remote-endpoint = <&disp0_out_tcon0>;
					};
				};
				tcon0_out: port@1 {
					#address-cells = <1>;
					#size-cells = <0>;
					reg = <1>;
					tcon0_out_lvds0: endpoint@0 {
						reg = <0>;
						remote-endpoint = <&lvds0_in_tcon0>;
					};
					tcon0_out_dsi0: endpoint@1 {
						reg = <1>;
						remote-endpoint = <&dsi0_in_tcon0>;
					};
					tcon0_out_rgb0: endpoint@2 {
						reg = <2>;
						remote-endpoint = <&rgb0_in_tcon0>;
					};
				};
			};
		};

		dsi0: dsi0@5506000 {
			compatible = "allwinner,dsi0";
			reg = <0x0 0x05506000 0x0 0xfff>;
			interrupts = <GIC_SPI 91 IRQ_TYPE_LEVEL_HIGH>;
			clocks = <&ccu CLK_DSI0>,
				<&ccu CLK_BUS_DSI0>,
				<&dsi0combophy CLK_DSI_HS>,
				<&dsi0combophy CLK_DSI_LS>;
			clock-names = "dsi_clk",
					"dsi_gating_clk",
					"displl_hs",
					"displl_ls";
			assigned-clocks = <&ccu CLK_DSI0>,
					<&ccu CLK_VO0_COMBPHY0>;
			assigned-clock-parents = <&ccu CLK_PLL_PERI0_150M>,
						<&ccu CLK_PLL_VIDEO0_4X>;
			resets = <&ccu RST_BUS_DSI0>;
			reset-names = "dsi_rst_clk";
			phys = <&dsi0combophy>;
			phy-names = "combophy";
			#address-cells = <1>;
			#size-cells = <0>;
			status = "disabled";

			ports {
				dsi0_in: port@0 {
					dsi0_in_tcon0: endpoint@0 {
						remote-endpoint = <&tcon0_out_dsi0>;
					};
				};
			};
		};

		dsi0combophy: phy@5507000 {
			compatible = "allwinner,sunxi-dsi-combo-phy0";
			reg = <0x0 0x05507000 0x0 0x1ff>;
			clocks = <&ccu CLK_BUS_DSI0>;
			clock-names = "phy_gating_clk";
			resets = <&ccu RST_BUS_DSI0>;
			reset-names = "phy_rst_clk";
			#clock-cells = <1>;
			#phy-cells = <0>;
			status = "disabled";
		};

		rgb0: rgb0@1000 {
			compatible = "allwinner,rgb0";
			clocks = <&dsi0combophy CLK_LVDS_OR_RGB>;
			clock-names = "rgb_pclk";
			status = "disabled";
			phys = <&dsi0combophy>;
			phy-names = "combophy0";
			ports {
				#address-cells = <1>;
				#size-cells = <0>;
				rgb0_in: port@0 {
					reg = <0>;
					rgb0_in_tcon0: endpoint@0 {
						remote-endpoint = <&tcon0_out_rgb0>;
					};
				};
				rgb0_out: port@1 {
					reg = <1>;
					rgb0_panel_out: endpoint@0 {
					//	remote-endpoint = <&rgb0_panel_in>>;
					};
				};

			};
		};

		lvds0: lvds0@1000 {
			compatible = "allwinner,lvds0";
			clocks = <&dsi0combophy CLK_LVDS_OR_RGB>;
			clock-names = "lvds_pclk";
			resets = <&ccu RST_BUS_LVDS0>;
			reset-names = "rst_bus_lvds";
			phys = <&dsi0combophy>;
			phy-names = "combophy0";
			status = "disabled";

			ports {
				#address-cells = <1>;
				#size-cells = <0>;
				lvds0_in: port@0 {
					reg = <0>;
					lvds0_in_tcon0: endpoint@0 {
						remote-endpoint = <&tcon0_out_lvds0>;
					};
				};
				lvds0_out: port@1 {
					reg = <1>;
					lvds0_panel_out: endpoint@0 {
					//	remote-endpoint = <&lvds_panel_in>>;
					};
				};
			};
		};
		pd_vo_test: pd_vo_test@0 {
			compatible = "allwinner,sunxi-power-domain-test";
			power-domains = <&pd MR536_PCK_VO>;
			status = "okay";
		};

		pd_vi_test: pd_vi_test@0 {
			compatible = "allwinner,sunxi-power-domain-test";
			power-domains = <&pd MR536_PCK_VI>;
			status = "okay";
		};

		pd_ve_test: pd_ve_test@0 {
			compatible = "allwinner,sunxi-power-domain-test";
			power-domains = <&pd MR536_PCK_VE>;
			status = "okay";
		};

		pd_npu_test: pd_npu_test@0 {
			compatible = "allwinner,sunxi-power-domain-test";
			power-domains = <&pd MR536_PCK_NPU>;
			status = "okay";
		};

		pd_serdes_test: pd_serdes_test@0 {
			compatible = "allwinner,sunxi-power-domain-test";
			power-domains = <&pd MR536_PCK_SERDES>;
			status = "okay";
		};

		sdc0: sdmmc@4020000 {
			compatible = "allwinner,sunxi-mmc-v5p3x";
			device_type = "sdc0";
			reg = <0x0 0x04020000 0x0 0x1000>;
			interrupts = <GIC_SPI 40 IRQ_TYPE_LEVEL_HIGH>;
						clocks = <&dcxo24M>,
						<&ccu CLK_PLL_PERI1_400M>,
						<&ccu CLK_PLL_PERI1_300M>,
						<&ccu CLK_SMHC0>,
						<&ccu CLK_BUS_SMHC0>;
			clock-names = "osc24m","pll_periph","pll_periph_2","mmc","ahb";
			resets = <&ccu RST_BUS_SMHC0>;
			reset-names = "rst";
			pinctrl-names = "default","mmc_1v8","sleep","uart_jtag";
			pinctrl-0 = <&sdc0_pins_a &sdc0_pins_f>;
			pinctrl-1 = <&sdc0_pins_b &sdc0_pins_g>;
			pinctrl-2 = <&sdc0_pins_c>;
			pinctrl-3 = <&sdc0_pins_d &sdc0_pins_e>;
			max-frequency = <50000000>;
			bus-width = <4>;
			req-page-count = <2>;
			/*non-removable;*/
			/*broken-cd;*/
			/*cd-inverted*/
			/*cd-gpios = <&pio PF 6 GPIO_ACTIVE_LOW>;*/
			/* vmmc-supply = <&reg_3p3v>;*/
			/* vqmc-supply = <&reg_3p3v>;*/
			/* vdmc-supply = <&reg_3p3v>;*/
			/*vmmc = "vcc-card";*/
			/*vqmc = "";*/
			/*vdmc = "";*/
			cap-sd-highspeed;
			cap-wait-while-busy;
			/*sd-uhs-sdr50;*/
			/*sd-uhs-ddr50;*/
			/*cap-sdio-irq;*/
			/*keep-power-in-suspend;*/
			/*ignore-pm-notify;*/
			/*sunxi-power-save-mode;*/
			/*sunxi-dly-400k = <1 0 0 0>; */
			/*sunxi-dly-26M  = <1 0 0 0>;*/
			/*sunxi-dly-52M  = <1 0 0 0>;*/
			/*sunxi-dly-52M-ddr4  = <1 0 0 0>;*/
			/*sunxi-dly-52M-ddr8  = <1 0 0 0>;*/
			/*sunxi-dly-104M  = <1 0 0 0>;*/
			/*sunxi-dly-208M  = <1 0 0 0>;*/
			/*sunxi-dly-104M-ddr  = <1 0 0 0>;*/
			/*sunxi-dly-208M-ddr  = <1 0 0 0>;*/
			execute_tuning_in_kernel;
			ctl-spec-caps = <0x428>;
			status = "disabled";
		};

		sdc1: sdmmc@4021000 {
			compatible = "allwinner,sunxi-mmc-v5p3x";
			device_type = "sdc1";
			reg = <0x0 0x04021000 0x0 0x1000>;
			interrupts = <GIC_SPI 41 IRQ_TYPE_LEVEL_HIGH>;
			clocks = <&dcxo24M>,
			 <&ccu CLK_PLL_PERI1_400M>,
			 <&ccu CLK_PLL_PERI1_300M>,
			 <&ccu CLK_SMHC1>,
			 <&ccu CLK_BUS_SMHC1>;
			clock-names = "osc24m","pll_periph","pll_periph_2","mmc","ahb";
			resets = <&ccu RST_BUS_SMHC1>;
			reset-names = "rst";
			pinctrl-names = "default","sleep";
			pinctrl-0 = <&sdc1_pins_a &sdc1_pins_c>;
			pinctrl-1 = <&sdc1_pins_b>;
			max-frequency = <50000000>;
			bus-width = <4>;
			/*broken-cd;*/
			/*cd-inverted*/
			/*cd-gpios = <&pio PG 6 6 1 2 0>;*/
			/* vmmc-supply = <&reg_3p3v>;*/
			/* vqmc-supply = <&reg_3p3v>;*/
			/* vdmc-supply = <&reg_3p3v>;*/
			/*vmmc = "vcc-card";*/
			/*vqmc = "";*/
			/*vdmc = "";*/
			cap-sd-highspeed;
			cap-sdio-irq;
			ignore-pm-notify;
			/*sd-uhs-sdr50;*/
			/*sd-uhs-ddr50;*/
			/*sd-uhs-sdr104;*/
			/*cap-sdio-irq;*/
			keep-power-in-suspend;
			/*ignore-pm-notify;*/
			/*sunxi-power-save-mode;*/
			/*sunxi-dly-400k = <0xff 0xff 0xff 0xff 0xff 0xff>; */
			/*sunxi-dly-26M  = <0xff 0xff 0xff 0xff 0xff 0xff>;*/
			/*sunxi-dly-52M  = <0xff 0xff 0xff 0xff 0xff 0xff>;*/
			/*sunxi-dly-52M-ddr4  = <0xff 0xff 0xff 0xff 0xff 0xff>;*/
			/*sunxi-dly-52M-ddr8  = <0xff 0xff 0xff 0xff 0xff 0xff>;*/
			/*sunxi-dly-104M  = <0xff 0xff 0xff 0xff 0xff 0xff>;*/
			/*sunxi-dly-208M  = <0xff 0xff 0xff 0xff 0xff 0xff> ;*/
			/*sunxi-dly-104M-ddr  = <0xff 0xff 0xff 0xff 0xff 0xff>;*/
			/*sunxi-dly-208M-ddr  = <0xff 0xff 0xff 0xff 0xff 0xff>;*/
			sunxi-dly-208M  = <0xff 0x1 0xff 0xff 0xff 0xff>;
			execute_tuning_in_kernel;
			ctl-spec-caps = <0x428>;
			status = "disabled";
		};

		dma0: dma-controller@3001000 {
			compatible = "allwinner,dma-v107";
			reg = <0x0 0x3001000 0x0 0x2000>;
			interrupts = <GIC_SPI 50 IRQ_TYPE_LEVEL_HIGH>,
				     <GIC_SPI 235 IRQ_TYPE_LEVEL_HIGH>;
			clocks = <&ccu CLK_DMA0>, <&ccu CLK_MBUS_DMA0_GATE>;
			clock-names = "bus", "mbus";
			dma-channels = <8>;
			dma-requests = <64>;
			resets = <&ccu RST_BUS_DMA0>;
			#dma-cells = <1>;
		};

		dma1: dma-controller@4000000 {
			compatible = "allwinner,dma-v107";
			reg = <0x0 0x4000000 0x0 0x2000>;
			interrupts = <GIC_SPI 164 IRQ_TYPE_LEVEL_HIGH>,
				     <GIC_SPI 236 IRQ_TYPE_LEVEL_HIGH>;
			clocks = <&ccu CLK_DMA1>, <&ccu CLK_MBUS_DMA1_GATE>;
			clock-names = "bus", "mbus";
			dma-channels = <16>;
			dma-requests = <64>;
			resets = <&ccu RST_BUS_DMA1>;
			#dma-cells = <1>;
		};

		gpadc0: gpadc@2087000 {
			compatible = "allwinner,sunxi-gpadc-v101";
			reg = <0x0 0x02087000 0x0 0x400>;
			interrupts = <GIC_SPI 61 IRQ_TYPE_LEVEL_HIGH>;
			clocks = <&ccu CLK_BUS_GPADC0>, <&ccu CLK_GPADC0>;
			clock-names = "bus", "hosc";
			resets = <&ccu RST_BUS_GPADC0>;
			status = "disabled";
		};

		gpadc1: gpadc@2088000 {
			compatible = "allwinner,sunxi-gpadc-v101";
			reg = <0x0 0x02088000 0x0 0x400>;
			interrupts = <GIC_SPI 64 IRQ_TYPE_LEVEL_HIGH>;
			clocks = <&ccu CLK_BUS_GPADC1>, <&ccu CLK_GPADC1>;
			clock-names = "bus", "hosc";
			resets = <&ccu RST_BUS_GPADC1>;
			status = "disabled";
		};

		gpadc2: gpadc@2089000 {
			compatible = "allwinner,sunxi-gpadc-v101";
			reg = <0x0 0x02089000 0x0 0x400>;
			interrupts = <GIC_SPI 62 IRQ_TYPE_LEVEL_HIGH>;
			clocks = <&ccu CLK_BUS_GPADC2>, <&ccu CLK_GPADC2>;
			clock-names = "bus", "hosc";
			resets = <&ccu RST_BUS_GPADC2>;
			status = "disabled";
		};

		gpadc3: gpadc@208a000 {
			compatible = "allwinner,sunxi-gpadc-v101";
			reg = <0x0 0x0208a000 0x0 0x400>;
			interrupts = <GIC_SPI 158 IRQ_TYPE_LEVEL_HIGH>;
			clocks = <&ccu CLK_BUS_GPADC3>, <&ccu CLK_GPADC3>;
			clock-names = "bus", "hosc";
			resets = <&ccu RST_BUS_GPADC3>;
			status = "disabled";
		};

		s_twi0: twi@7083000 {
			#address-cells = <1>;
			#size-cells = <0>;
			compatible = "allwinner,sunxi-twi-v101";
			device_type = "s_twi0";
			reg = <0x0 0x07083000 0x0 0x400>;
			interrupts = <GIC_SPI 207 IRQ_TYPE_LEVEL_HIGH>;
			clocks = <&r_ccu CLK_R_TWI0>;
			clock-names = "bus";
			resets = <&r_ccu RST_BUS_R_TWI0>;
			dmas = <&dma0 49>, <&dma0 49>;
			dma-names = "tx", "rx";
			status = "disabled";
		};

		s_twi1: twi@7084000 {
			#address-cells = <1>;
			#size-cells = <0>;
			compatible = "allwinner,sunxi-twi-v101";
			device_type = "s_twi1";
			reg = <0x0 0x07084000 0x0 0x400>;
			interrupts = <GIC_SPI 208 IRQ_TYPE_LEVEL_HIGH>;
			clocks = <&r_ccu CLK_R_TWI1>;
			clock-names = "bus";
			resets = <&r_ccu RST_BUS_R_TWI1>;
			dmas = <&dma0 50>, <&dma0 50>;
			dma-names = "tx", "rx";
			status = "disabled";
		};

		twi0: twi@2510000 {
			#address-cells = <1>;
			#size-cells = <0>;
			compatible = "allwinner,sunxi-twi-v101";
			device_type = "twi0";
			reg = <0x0 0x02510000 0x0 0x400>;
			interrupts = <GIC_SPI 10 IRQ_TYPE_LEVEL_HIGH>;
			clocks = <&ccu CLK_TWI0>;
			clock-names = "bus";
			resets = <&ccu RST_BUS_TWI0>;
			dmas = <&dma0 43>, <&dma0 43>;
			dma-names = "tx", "rx";
			status = "disabled";
		};

		twi1: twi@2511000 {
			#address-cells = <1>;
			#size-cells = <0>;
			compatible = "allwinner,sunxi-twi-v101";
			device_type = "twi1";
			reg = <0x0 0x02511000 0x0 0x400>;
			interrupts = <GIC_SPI 11 IRQ_TYPE_LEVEL_HIGH>;
			clocks = <&ccu CLK_TWI1>;
			clock-names = "bus";
			resets = <&ccu RST_BUS_TWI1>;
			dmas = <&dma0 44>, <&dma0 44>;
			dma-names = "tx", "rx";
			status = "disabled";
		};

		twi2: twi@2512000 {
			#address-cells = <1>;
			#size-cells = <0>;
			compatible = "allwinner,sunxi-twi-v101";
			device_type = "twi2";
			reg = <0x0 0x02512000 0x0 0x400>;
			interrupts = <GIC_SPI 12 IRQ_TYPE_LEVEL_HIGH>;
			clocks = <&ccu CLK_TWI2>;
			clock-names = "bus";
			resets = <&ccu RST_BUS_TWI2>;
			dmas = <&dma0 45>, <&dma0 45>;
			dma-names = "tx", "rx";
			status = "disabled";
		};

		twi3: twi@2513000 {
			#address-cells = <1>;
			#size-cells = <0>;
			compatible = "allwinner,sunxi-twi-v101";
			device_type = "twi3";
			reg = <0x0 0x02513000 0x0 0x400>;
			interrupts = <GIC_SPI 13 IRQ_TYPE_LEVEL_HIGH>;
			clocks = <&ccu CLK_TWI3>;
			clock-names = "bus";
			resets = <&ccu RST_BUS_TWI3>;
			dmas = <&dma0 46>, <&dma0 46>;
			dma-names = "tx", "rx";
			status = "disabled";
		};

		twi4: twi@2514000 {
			#address-cells = <1>;
			#size-cells = <0>;
			compatible = "allwinner,sunxi-twi-v101";
			device_type = "twi4";
			reg = <0x0 0x02514000 0x0 0x400>;
			interrupts = <GIC_SPI 14 IRQ_TYPE_LEVEL_HIGH>;
			clocks = <&ccu CLK_TWI4>;
			clock-names = "bus";
			resets = <&ccu RST_BUS_TWI4>;
			dmas = <&dma0 47>, <&dma0 47>;
			dma-names = "tx", "rx";
			status = "disabled";
		};

		twi5: twi@2515000 {
			#address-cells = <1>;
			#size-cells = <0>;
			compatible = "allwinner,sunxi-twi-v101";
			device_type = "twi5";
			reg = <0x0 0x02515000 0x0 0x400>;
			interrupts = <GIC_SPI 15 IRQ_TYPE_LEVEL_HIGH>;
			clocks = <&ccu CLK_TWI5>;
			clock-names = "bus";
			resets = <&ccu RST_BUS_TWI5>;
			dmas = <&dma0 48>, <&dma0 48>;
			dma-names = "tx", "rx";
			status = "disabled";
		};

		twi6: twi@2516000 {
			#address-cells = <1>;
			#size-cells = <0>;
			compatible = "allwinner,sunxi-twi-v101";
			device_type = "twi6";
			reg = <0x0 0x02516000 0x0 0x400>;
			interrupts = <GIC_SPI 155 IRQ_TYPE_LEVEL_HIGH>;
			clocks = <&ccu CLK_TWI6>;
			clock-names = "bus";
			resets = <&ccu RST_BUS_TWI6>;
			dmas = <&dma0 62>, <&dma0 62>;
			dma-names = "tx", "rx";
			status = "disabled";
		};

		spi0: spi@4025000 {
			#address-cells = <1>;
			#size-cells = <0>;
			compatible = "allwinner,sunxi-spi-v1.5";
			reg = <0x0 0x04025000 0x0 0x1000>;
			interrupts = <GIC_SPI 16 IRQ_TYPE_LEVEL_HIGH>;
			clocks = <&ccu CLK_PLL_PERI0_300M>, <&ccu CLK_SPI0>, <&ccu CLK_BUS_SPI0>, <&ccu CLK_AHB>;
			clock-names = "pll", "mod", "bus", "ahb";
			resets = <&ccu RST_BUS_SPI0>;
			dmas = <&dma0 22>, <&dma0 22>;
			dma-names = "tx", "rx";
			clock-frequency = <100000000>;
			sunxi,spi-num-cs = <2>;
			status = "disabled";
		};

		spi1: spi@4026000 {
			#address-cells = <1>;
			#size-cells = <0>;
			compatible = "allwinner,sunxi-spi-v1.6";
			reg = <0x0 0x04026000 0x0 0x1000>;
			interrupts = <GIC_SPI 17 IRQ_TYPE_LEVEL_HIGH>;
			clocks = <&ccu CLK_PLL_PERI0_300M>, <&ccu CLK_SPI1>, <&ccu CLK_BUS_SPI1>, <&ccu CLK_AHB>;
			clock-names = "pll", "mod", "bus", "ahb";
			resets = <&ccu RST_BUS_SPI1>;
			dmas = <&dma0 23>, <&dma0 23>;
			dma-names = "tx", "rx";
			clock-frequency = <100000000>;
			sunxi,spi-num-cs = <1>;
			status = "disabled";
		};

		spi2: spi@4027000 {
			#address-cells = <1>;
			#size-cells = <0>;
			compatible = "allwinner,sunxi-spi-v1.5";
			reg = <0x0 0x04027000 0x0 0x1000>;
			interrupts = <GIC_SPI 18 IRQ_TYPE_LEVEL_HIGH>;
			clocks = <&ccu CLK_PLL_PERI0_300M>, <&ccu CLK_SPI2>, <&ccu CLK_BUS_SPI2>, <&ccu CLK_AHB>;
			clock-names = "pll", "mod", "bus", "ahb";
			resets = <&ccu RST_BUS_SPI2>;
			dmas = <&dma0 24>, <&dma0 24>;
			dma-names = "tx", "rx";
			clock-frequency = <100000000>;
			sunxi,spi-num-cs = <1>;
			status = "disabled";
		};

		spi3: spi@4028000 {
			#address-cells = <1>;
			#size-cells = <0>;
			compatible = "allwinner,sunxi-spi-v1.5";
			reg = <0x0 0x04028000 0x0 0x1000>;
			interrupts = <GIC_SPI 21 IRQ_TYPE_LEVEL_HIGH>;
			clocks = <&ccu CLK_PLL_PERI0_300M>, <&ccu CLK_SPI3>, <&ccu CLK_BUS_SPI3>, <&ccu CLK_AHB>;
			clock-names = "pll", "mod", "bus", "ahb";
			resets = <&ccu RST_BUS_SPI3>;
			dmas = <&dma0 25>, <&dma0 25>;
			dma-names = "tx", "rx";
			clock-frequency = <100000000>;
			sunxi,spi-num-cs = <1>;
			status = "disabled";
		};

		spi4: spi@4029000 {
			#address-cells = <1>;
			#size-cells = <0>;
			compatible = "allwinner,sunxi-spi-v1.5";
			reg = <0x0 0x04029000 0x0 0x1000>;
			interrupts = <GIC_SPI 22 IRQ_TYPE_LEVEL_HIGH>;
			clocks = <&ccu CLK_PLL_PERI0_300M>, <&ccu CLK_SPI4>, <&ccu CLK_BUS_SPI4>, <&ccu CLK_AHB>;
			clock-names = "pll", "mod", "bus", "ahb";
			resets = <&ccu RST_BUS_SPI4>;
			dmas = <&dma0 26>, <&dma0 26>;
			dma-names = "tx", "rx";
			clock-frequency = <100000000>;
			sunxi,spi-num-cs = <1>;
			status = "disabled";
		};

		r_spi0: spi@7092000 {
			#address-cells = <1>;
			#size-cells = <0>;
			compatible = "allwinner,sunxi-spi-v1.5";
			reg = <0x0 0x07092000 0x0 0x1000>;
			interrupts = <GIC_SPI 214 IRQ_TYPE_LEVEL_HIGH>;
			clocks = <&ccu CLK_PLL_PERI0_300M>, <&r_ccu CLK_R_SPI>, <&r_ccu CLK_R_BUS_SPI>, <&ccu CLK_AHB>;
			clock-names = "pll", "mod", "bus", "ahb";
			resets = <&r_ccu RST_BUS_R_SPI>;
			dmas = <&dma0 53>, <&dma0 53>;
			dma-names = "tx", "rx";
			clock-frequency = <100000000>;
			sunxi,spi-num-cs = <1>;
			status = "disabled";
		};

		spif0: spif@2800000 {
			#address-cells = <1>;
			#size-cells = <0>;
			compatible = "allwinner,sun55i-spif";
			device_type = "spif";
			reg = <0x0 0x02800000 0x0 0x1000>;
			interrupts = <GIC_SPI 20 IRQ_TYPE_LEVEL_HIGH>;
			clocks = <&ccu CLK_PLL_PERI0_400M>, <&ccu CLK_SPIF>, <&ccu CLK_BUS_SPIF>;
			clock-names = "pclk", "mclk", "bus";
			resets = <&ccu RST_BUS_SPIF>;
			clock-frequency = <100000000>;
			status = "disabled";
		};

		nand0:nand0@4011000 {
			compatible = "allwinner,sun55iw6-nand";
				device_type = "nand0";
				reg = <0x0 0x04011000 0x0 0x1000>;/* nand0 */
				interrupts = <GIC_SPI 38 IRQ_TYPE_LEVEL_HIGH>;
				clocks = <&ccu CLK_PLL_PERI0_300M>,
						<&ccu CLK_NAND0>,
					<&ccu CLK_NAND0_CLK2X>,
					<&ccu CLK_BUS_NAND0>,
					<&ccu CLK_MBUS_NAND_GATE>;
				clock-names = "pll_periph", "mclk","ecc", "bus", "mbus";
				resets = <&ccu RST_BUS_NAND0>;
				reset-names = "rst";
				nand0_regulator1 = "vcc-nand";
				nand0_regulator2 = "none";
				nand0_cache_level = <0x55aaaa55>;
				nand0_flush_cache_num = <0x55aaaa55>;
				nand0_capacity_level = <0x55aaaa55>;
				nand0_id_number_ctl = <0x55aaaa55>;
				nand0_print_level = <0x55aaaa55>;
				nand0_p0 = <0x55aaaa55>;
				nand0_p1 = <0x55aaaa55>;
				nand0_p2 = <0x55aaaa55>;
				nand0_p3 = <0x55aaaa55>;
				chip_code = "sun55iw6";
				dmas = <&dma0 10>, <&dma0 10>;
				dma-names = "tx", "rx";
				status = "disabled";
				boot_crc = "disabled";
		};

		hwspinlock: hwspinlock@3005000 {
			compatible = "allwinner,sunxi-hwspinlock";
			reg = <0x0 0x3005000 0x0 0x1000>;
			#hwlock-cells = <1>;
			clocks = <&ccu CLK_SPINLOCK>;
			clock-names = "clk_hwspinlock_bus";
			resets = <&ccu RST_BUS_SPINLOCK>;
			reset-names = "rst";
			num-locks = <32>;
			status = "disabled";
		};

		mailbox_test: mailbox_test@0 {
			compatible = "mailbox-test";
			mboxes = <&msgbox 7>; /* rv channel3 */
			mbox-names = "tx|rx";
			status = "disabled";
		};

		/*
		 * channel0~3  : arm -> cpus
		 * channel4~7 : arm -> RV
		 */
		msgbox: msgbox@3003000 {
			compatible = "allwinner,sun55iw6-msgbox";
			#mbox-cells = <1>;
			reg = <0x0 0x03003000 0x0 0x1000>,
			      <0x0 0x07094000 0x0 0x1000>,
			      <0x0 0x01a06000 0x0 0x1000>;
			interrupts = <GIC_SPI 0 IRQ_TYPE_LEVEL_HIGH>,
				     <GIC_SPI 215 IRQ_TYPE_LEVEL_HIGH>,
				     <GIC_SPI 183 IRQ_TYPE_LEVEL_HIGH>;
			clocks = <&ccu CLK_MSGBOX0>;
			clock-names = "msgbox";
			resets = <&ccu RST_BUS_MSGBOX0>;
			reset-names = "rst";
			local_id = <0>;
			status = "disabled";
		};

		e907_rproc: e907_rproc@1a00000 {
			reg = <0x0 0x1a00000 0x0 0x1000>,
				<0x0 0x01a02000 0x0 0x400>;
			compatible = "allwinner,e907-rproc";
			core-clock-frequency = <600000000>;
			axi-clock-frequency = <300000000>;
			clocks = <&ccu CLK_PLL_PERI0_600M>, <&ccu CLK_RV_CORE>, <&ccu CLK_RV_TS>, <&ccu CLK_RV_CFG>, <&ccu CLK_E907_AXI>;
			clock-names = "input", "core-gate", "rv-ts-gate", "rv-cfg-gate", "axi-div";
			resets = <&ccu RST_BUS_RV_CFG>, <&ccu RST_BUS_RV_CORE>, <&ccu RST_BUS_RV_SY>;
			reset-names = "rv-cfg-rst", "core-rst", "rv-sys-rst";

			firmware-name = "amp_rv0.bin";
			reg-names = "rv-cfg", "rproc_wdt_reg";

			interrupts = <GIC_SPI 185 IRQ_TYPE_LEVEL_HIGH>;
			interrupt-names = "rproc_wdt_irq";
			status = "disabled";
		};

		pwm0: pwm@2090000 {
			#pwm-cells = <0x3>;
			compatible = "allwinner,sunxi-pwm-v203";
			reg = <0x0 0x02090000 0x0 0x400>;
			clocks = <&ccu CLK_PWM0>;
			interrupts = <GIC_SPI 19 IRQ_TYPE_LEVEL_HIGH>;
			resets = <&ccu RST_BUS_PWM0>;
			pwm-number = <10>;
			pwm-base = <0x0>;
			sunxi-pwms = <&pwm0_0>, <&pwm0_1>, <&pwm0_2>, <&pwm0_3>, <&pwm0_4>,
			<&pwm0_5>, <&pwm0_6>, <&pwm0_7>, <&pwm0_8>, <&pwm0_9>;
			status = "okay";
		};

		pwm0_0: pwm@2090010 {
			compatible = "allwinner,sunxi-pwm0";
			reg = <0x0 0x02090010 0x0 0x4>;
			reg_base = <0x02090000>;
			status = "disabled";
		};

		pwm0_1: pwm@2090011 {
			compatible = "allwinner,sunxi-pwm1";
			reg = <0x0 0x02090011 0x0 0x4>;
			reg_base = <0x02090000>;
			status = "disabled";
		};

		pwm0_2: pwm@2090012 {
			compatible = "allwinner,sunxi-pwm2";
			reg = <0x0 0x02090012 0x0 0x4>;
			reg_base = <0x02090000>;
			status = "disabled";
		};

		pwm0_3: pwm0@2090013 {
			compatible = "allwinner,sunxi-pwm3";
			reg = <0x0 0x02090013 0x0 0x4>;
			reg_base = <0x02090000>;
			status = "disabled";
		};

		pwm0_4: pwm@2090014 {
			compatible = "allwinner,sunxi-pwm4";
			reg = <0x0 0x02090014 0x0 0x4>;
			reg_base = <0x02090000>;
			status = "disabled";
		};

		pwm0_5: pwm@2090015 {
			compatible = "allwinner,sunxi-pwm5";
			reg = <0x0 0x02090015 0x0 0x4>;
			reg_base = <0x02090000>;
			status = "disabled";
		};

		pwm0_6: pwm@2090016 {
			compatible = "allwinner,sunxi-pwm6";
			reg = <0x0 0x02090016 0x0 0x4>;
			reg_base = <0x02090000>;
			status = "disabled";
		};

		pwm0_7: pwm@2090017 {
			compatible = "allwinner,sunxi-pwm7";
			reg = <0x0 0x02090017 0x0 0x4>;
			reg_base = <0x02090000>;
			status = "disabled";
		};

		pwm0_8: pwm@2090018 {
			compatible = "allwinner,sunxi-pwm8";
			reg = <0x0 0x02090018 0x0 0x4>;
			reg_base = <0x02090000>;
			status = "disabled";
		};

		pwm0_9: pwm@2090019 {
			compatible = "allwinner,sunxi-pwm9";
			reg = <0x0 0x02090019 0x0 0x4>;
			reg_base = <0x02090000>;
			status = "disabled";
		};

		pwm1: pwm@2091000 {
			#pwm-cells = <0x3>;
			compatible = "allwinner,sunxi-pwm-v203";
			reg = <0x0 0x02091000 0x0 0x400>;
			clocks = <&ccu CLK_PWM1>;
			interrupts = <GIC_SPI 142 IRQ_TYPE_LEVEL_HIGH>;
			resets = <&ccu RST_BUS_PWM1>;
			pwm-number = <10>;
			pwm-base = <0xa>;
			sunxi-pwms = <&pwm1_0>, <&pwm1_1>, <&pwm1_2>, <&pwm1_3>,
			<&pwm1_4>, <&pwm1_5>, <&pwm1_6>, <&pwm1_7>, <&pwm1_8>, <&pwm1_9>;
			status = "okay";
		};

		pwm1_0: pwm@2091010 {
			compatible = "allwinner,sunxi-pwm10";
			reg = <0x0 0x02091010 0x0 0x4>;
			reg_base = <0x02091000>;
			status = "disabled";
		};

		pwm1_1: pwm@2091011 {
			compatible = "allwinner,sunxi-pwm11";
			reg = <0x0 0x02091011 0x0 0x4>;
			reg_base = <0x02091000>;
			status = "disabled";
		};

		pwm1_2: pwm@2091012 {
			compatible = "allwinner,sunxi-pwm12";
			reg = <0x0 0x02091012 0x0 0x4>;
			reg_base = <0x02091000>;
			status = "disabled";
		};

		pwm1_3: pwm@2091013 {
			compatible = "allwinner,sunxi-pwm13";
			reg = <0x0 0x02091013 0x0 0x4>;
			reg_base = <0x02091000>;
			status = "disabled";
		};

		pwm1_4: pwm@2091014 {
			compatible = "allwinner,sunxi-pwm14";
			reg = <0x0 0x02091014 0x0 0x4>;
			reg_base = <0x02091000>;
			status = "disabled";
		};

		pwm1_5: pwm@2091015 {
			compatible = "allwinner,sunxi-pwm15";
			reg = <0x0 0x02091015 0x0 0x4>;
			reg_base = <0x02091000>;
			status = "disabled";
		};

		pwm1_6: pwm@2091016 {
			compatible = "allwinner,sunxi-pwm16";
			reg = <0x0 0x02091016 0x0 0x4>;
			reg_base = <0x02091000>;
			status = "disabled";
		};

		pwm1_7: pwm@2091017 {
			compatible = "allwinner,sunxi-pwm17";
			reg = <0x0 0x02091017 0x0 0x4>;
			reg_base = <0x02091000>;
			status = "disabled";
		};

		pwm1_8: pwm@2091018 {
			compatible = "allwinner,sunxi-pwm18";
			reg = <0x0 0x02091018 0x0 0x4>;
			reg_base = <0x02091000>;
			status = "disabled";
		};

		pwm1_9: pwm@2091019 {
			compatible = "allwinner,sunxi-pwm19";
			reg = <0x0 0x02091019 0x0 0x4>;
			reg_base = <0x02091000>;
			status = "disabled";
		};

		pwm2: pwm@2092000 {
			#pwm-cells = <0x3>;
			compatible = "allwinner,sunxi-pwm-v203";
			reg = <0x0 0x02092000 0x0 0x400>;
			clocks = <&ccu CLK_PWM2>;
			interrupts = <GIC_SPI 45 IRQ_TYPE_LEVEL_HIGH>;
			resets = <&ccu RST_BUS_PWM2>;
			pwm-number = <10>;
			pwm-base = <0x14>;
			sunxi-pwms = <&pwm2_0>, <&pwm2_1>, <&pwm2_2>, <&pwm2_3>,
			<&pwm2_4>, <&pwm2_5>, <&pwm2_6>, <&pwm2_7>, <&pwm2_8>, <&pwm2_9>;
			status = "okay";
		};

		pwm2_0: pwm@2092010 {
			compatible = "allwinner,sunxi-pwm20";
			reg = <0x0 0x02092010 0x0 0x4>;
			reg_base = <0x02092000>;
			status = "disabled";
		};

		pwm2_1: pwm@2092011 {
			compatible = "allwinner,sunxi-pwm21";
			reg = <0x0 0x02092011 0x0 0x4>;
			reg_base = <0x02092000>;
			status = "disabled";
		};

		pwm2_2: pwm@2092012 {
			compatible = "allwinner,sunxi-pwm22";
			reg = <0x0 0x02092012 0x0 0x4>;
			reg_base = <0x02092000>;
			status = "disabled";
		};

		pwm2_3: pwm@2092013 {
			compatible = "allwinner,sunxi-pwm23";
			reg = <0x0 0x02092013 0x0 0x4>;
			reg_base = <0x02092000>;
			status = "disabled";
		};

		pwm2_4: pwm@2092014 {
			compatible = "allwinner,sunxi-pwm24";
			reg = <0x0 0x02092014 0x0 0x4>;
			reg_base = <0x02092000>;
			status = "disabled";
		};

		pwm2_5: pwm@2092015 {
			compatible = "allwinner,sunxi-pwm25";
			reg = <0x0 0x02092015 0x0 0x4>;
			reg_base = <0x02092000>;
			status = "disabled";
		};

		pwm2_6: pwm@2092016 {
			compatible = "allwinner,sunxi-pwm26";
			reg = <0x0 0x02092016 0x0 0x4>;
			reg_base = <0x02092000>;
			status = "disabled";
		};

		pwm2_7: pwm@2092017 {
			compatible = "allwinner,sunxi-pwm27";
			reg = <0x0 0x02092017 0x0 0x4>;
			reg_base = <0x02092000>;
			status = "disabled";
		};

		pwm2_8: pwm@2092018 {
			compatible = "allwinner,sunxi-pwm28";
			reg = <0x0 0x02092018 0x0 0x4>;
			reg_base = <0x02092000>;
			status = "disabled";
		};

		pwm2_9: pwm@2092019 {
			compatible = "allwinner,sunxi-pwm29";
			reg = <0x0 0x02092019 0x0 0x4>;
			reg_base = <0x02092000>;
			status = "disabled";
		};

		s_pwm: s_pwm@7023000 {
			#pwm-cells = <0x3>;
			compatible = "allwinner,sunxi-pwm-v204";
			reg = <0x0 0x07023000 0x0 0x400>;
			clocks = <&r_ccu CLK_R_PWM>,<&r_ccu CLK_R_BUS_PWM>;
			interrupts = <GIC_SPI 211 IRQ_TYPE_LEVEL_HIGH>;
			clock-names = "clk_pwm","clk_bus_pwm";
			resets = <&r_ccu RST_BUS_R_PWM>;
			pwm-number = <4>;
			pwm-base = <0x1e>;
			sunxi-pwms = <&s_pwm0>, <&s_pwm1>, <&s_pwm2>, <&s_pwm3>;
			status = "okay";
		};

		s_pwm0: s_pwm@7023010 {
			compatible = "allwinner,sunxi-pwm30";
			reg = <0x0 0x07023010 0x0 0x4>;
			reg_base = <0x07023000>;
			status = "disabled";
		};

		s_pwm1: s_pwm@7023011 {
			compatible = "allwinner,sunxi-pwm31";
			reg = <0x0 0x07023011 0x0 0x4>;
			reg_base = <0x07023000>;
			status = "disabled";
		};

		s_pwm2: s_pwm@7023012 {
			compatible = "allwinner,sunxi-pwm32";
			reg = <0x0 0x07023012 0x0 0x4>;
			reg_base = <0x07023000>;
			status = "disabled";
		};

		s_pwm3: s_pwm@7023013 {
			compatible = "allwinner,sunxi-pwm33";
			reg = <0x0 0x07023013 0x0 0x4>;
			reg_base = <0x07023000>;
			status = "disabled";
		};

		usbc0: usbc0@10 {
			device_type = "usbc0";
			compatible = "allwinner,sunxi-otg-manager";
			reg = <0x0 0x10 0x0 0x1000>;
			usb_port_type = <2>;
			usb_detect_type = <1>;
			usb_detect_mode = <0>;
			usb_id_gpio;
			usb_det_vbus_gpio;
			usb_regulator_io = "nocare";
			usb_wakeup_suspend = <0>;
			usb_luns = <3>;
			usb_serial_unique = <0>;
			usb_serial_number = "20080411";
			rndis_wceis = <1>;
			status = "disabled";
		};

		udc:udc-controller@4100000 {
			compatible = "allwinner,sunxi-udc";
			reg = <0x0 0x04100000 0x0 0x1000>, /*udc base*/
			      <0x0 0x00000000 0x0 0x100>;  /*sram base*/
			interrupts = <GIC_SPI 29 IRQ_TYPE_LEVEL_HIGH>;
			clocks = <&ccu CLK_USB0_USB1_24M>, <&ccu CLK_USB20_0_DEVICE>;
			clock-names = "hosc", "bus_otg";
			resets = <&ccu RST_USB_20_0_DEVICE>, <&ccu RST_USB_PHY0_RSTN>;
			reset-names = "otg", "phy";
			status = "disabled";
		};

		ehci0:ehci0-controller@4101000 {
			compatible = "allwinner,sunxi-ehci0";
			reg = <0x0 0x04101000 0x0 0xFFF>,  /*hci0 base*/
			      <0x0 0x00000000 0x0 0x100>,  /*sram base*/
			      <0x0 0x04100000 0x0 0x1000>; /*otg base*/
			interrupts = <GIC_SPI 30 IRQ_TYPE_LEVEL_HIGH>;
			clocks = <&ccu CLK_USB0_USB1_24M>, <&ccu CLK_USB20_0_HOST_EHCI>;
			clock-names = "hosc", "bus_hci";
			resets = <&ccu RST_USB_20_0_HOST_EHCI>, <&ccu RST_USB_PHY0_RSTN>;
			reset-names = "hci", "phy";
			hci_ctrl_no = <0>;
			status = "disabled";
		};

		ohci0:ohci0-controller@4101400 {
			compatible = "allwinner,sunxi-ohci0";
			reg = <0x0 0x04101400 0x0 0xFFF>,  /*hci0 base*/
			      <0x0 0x00000000 0x0 0x100>,  /*sram base*/
			      <0x0 0x04100000 0x0 0x1000>; /*otg base*/
			interrupts = <GIC_SPI 31 IRQ_TYPE_LEVEL_HIGH>;
			clocks = <&ccu CLK_USB0_USB1_24M>, <&ccu CLK_USB20_0_HOST_OHCI>, <&ccu CLK_USB>;
			clock-names = "hosc", "bus_hci", "ohci";
			resets = <&ccu RST_USB_20_0_HOST_OHCI>, <&ccu RST_USB_PHY0_RSTN>;
			reset-names = "hci", "phy";
			hci_ctrl_no = <0>;
			status = "disabled";
		};

		usbc1: usbc1@11 {
			device_type = "usbc1";
			reg = <0x0 0x11 0x0 0x1000>;
			usb_regulator_io = "nocare";
			usb_wakeup_suspend = <0>;
			status = "disabled";
		};

		ehci1: ehci1-controller@4200000 {
			compatible = "allwinner,sunxi-ehci1";
			reg = <0x0 0x04200000 0x0 0xFFF>,  /*ehci1 base*/
			      <0x0 0x00000000 0x0 0x100>,  /*sram base*/
			      <0x0 0x04100000 0x0 0x1000>; /*otg base*/
			interrupts = <GIC_SPI 32 IRQ_TYPE_LEVEL_HIGH>;
			clocks = <&ccu CLK_USB0_USB1_24M>, <&ccu CLK_USB20_1_HOST_EHCI>;
			clock-names = "hosc", "bus_hci";
			resets = <&ccu RST_USB_20_1_HOST_EHCI>, <&ccu RST_USB_PHY1_RSTN>;
			reset-names = "hci", "phy";
			hci_ctrl_no = <1>;
			status = "disabled";
		};

		ohci1: ohci1-controller@4200400 {
			compatible = "allwinner,sunxi-ohci1";
			reg = <0x0 0x04200400 0x0 0xFFF>,  /*ohci1 base*/
			      <0x0 0x00000000 0x0 0x100>,  /*sram base*/
			      <0x0 0x04100000 0x0 0x1000>; /*otg base*/
			interrupts = <GIC_SPI 33 IRQ_TYPE_LEVEL_HIGH>;
			clocks = <&ccu CLK_USB0_USB1_24M>, <&ccu CLK_USB20_1_HOST_OHCI>, <&ccu CLK_USB1>;
			clock-names = "hosc", "bus_hci", "ohci";
			resets = <&ccu RST_USB_20_1_HOST_OHCI>, <&ccu RST_USB_PHY1_RSTN>;
			reset-names = "hci", "phy";
			hci_ctrl_no = <1>;
			status = "disabled";
		};

		usbc2:usbc2@12 {
			device_type = "usbc2";
			compatible = "allwinner,sunxi-plat-dwc3";
			reg = <0x0 0x12 0x0 0x1000>;
			#address-cells = <2>;
			#size-cells = <2>;
			ranges;
			aw,hcgen2-phygen1-quirk;
			status = "disabled";

			xhci2: xhci2-controller@4d00000 {
				compatible = "snps,dwc3";
				reg = <0x0 0x04d00000 0x0 0x100000>;
				interrupts = <GIC_SPI 34 IRQ_TYPE_LEVEL_HIGH>;
				dr_mode = "otg"; // dr_mode option: host, peripheral, otg
				clocks = <&ccu CLK_USB30>, <&ccu CLK_USB3_REF>,
					 <&ccu CLK_USB2_REF>, <&ccu CLK_USB2_SUSPEND>;
				clock-names = "bus_clk", "ref_clk3", "ref_clk2", "suspend";
				resets = <&ccu RST_USB_30>;
				reset-names = "hci";
				maximum-speed = "super-speed";
				phy_type = "utmi";
				snps,dis_enblslpm_quirk;
				snps,dis-u1-entry-quirk;
				snps,dis-u2-entry-quirk;
				snps,dis_u3_susphy_quirk;
				snps,dis_u2_susphy_quirk;
				phys = <&u2phy>, <&combophy PHY_TYPE_USB3>;
				phy-names = "usb2-phy", "usb3-phy";
				status = "disabled";
			};
		};

		u2phy: phy@4e00000 {
			compatible = "allwinner,sunxi-plat-phy-v2";
			reg = <0x0 0x04e00000 0x0 0x800>; /* Application Registers */
			#phy-cells = <0>;
			status = "disabled";
		};

		combophy: phy@4f00000 {
			compatible = "allwinner,inno-v2-combphy";
			reg = <0x0 0x04f00000 0x0 0x80000>, /* Sub-System Application Registers */
			      <0x0 0x04f80000 0x0 0x80000>; /* Combo INNO PHY Registers */
			reg-names = "phy-ctl", "phy-clk";
			power-domains = <&pd MR536_PCK_SERDES>;
			phy_refclk_sel = <0>; /* 0:internal clk; 1:external clk */
			clocks = <&ccu CLK_SERDES_PHY_REF>,<&ccu CLK_PLL_PERI0_600M>,<&ccu CLK_SERDES_PHY_CFG>,
				<&ccu CLK_PLL_PERI0_400M>,<&ccu CLK_BUS_SERDES>,<&ccu CLK_AHB_SERDES>,
				<&ccu CLK_SERDES_AXI>, <&ccu CLK_PLL_PERI0_480M>;
			clock-names = "phyclk_ref","refclk_par","phyclk_cfg","cfgclk_par",
					"phy_mclk","phy_hclk","pclk_axi", "pclk_axi_par";
			resets = <&ccu RST_BUS_SERDE>, <&ccu RST_BUS_SERDES_NOPPU>;
			reset-names = "phy_rst", "noppu_rst";
			#phy-cells = <1>;
			status = "disabled";
		};

		pcie: pcie@4800000 {
			compatible = "allwinner,sunxi-pcie-v210-v2-rc";
			#address-cells = <3>;
			#size-cells = <2>;
			bus-range = <0x0 0xff>;
			reg = <0 0x04800000 0 0x480000>;
			reg-names = "dbi";
			device_type = "pci";
			ranges = <0x00000800 0 0x20000000 0x0 0x20000000 0 0x01000000
						0x81000000 0 0x21000000 0x0 0x21000000 0 0x01000000
						0x82000000 0 0x22000000 0x0 0x22000000 0 0x06000000>;

			num-lanes = <1>;
			phys = <&combophy PHY_TYPE_PCIE>;
			phy-names = "pcie-phy";
			interrupts = <GIC_SPI 107 IRQ_TYPE_LEVEL_HIGH>,
				     <GIC_SPI 106 IRQ_TYPE_LEVEL_HIGH>,
				     <GIC_SPI 98  IRQ_TYPE_LEVEL_HIGH>,
				     <GIC_SPI 99  IRQ_TYPE_LEVEL_HIGH>,
				     <GIC_SPI 100 IRQ_TYPE_LEVEL_HIGH>,
				     <GIC_SPI 101 IRQ_TYPE_LEVEL_HIGH>,
				     <GIC_SPI 102 IRQ_TYPE_LEVEL_HIGH>,
				     <GIC_SPI 103 IRQ_TYPE_LEVEL_HIGH>,
				     <GIC_SPI 104 IRQ_TYPE_LEVEL_HIGH>,
				     <GIC_SPI 105 IRQ_TYPE_LEVEL_HIGH>;
			interrupt-names = "msi", "sii", "edma-w0", "edma-w1", "edma-w2", "edma-w3",
					  "edma-r0", "edma-r1", "edma-r2", "edma-r3";
			#interrupt-cells = <1>;
			num-edma = <4>;
			max-link-speed = <2>;
			num-ib-windows = <8>;
			num-ob-windows = <8>;
			linux,pci-domain = <0>;
			power-domains = <&pd MR536_PCK_SERDES>;
			clocks =  <&dcxo24M>, <&ccu CLK_PCIE_REF_AUX>,<&ccu CLK_PCIE_SLV>;
			clock-names =  "hosc", "pclk_aux","pclk_slv";
			resets = <&ccu RST_BUS_PCIE>, <&ccu RST_BUS_PCIE_PWRUP>;
			reset-names = "pclk_rst", "pwrup_rst";
			status = "disabled";
		};

		rfkill: rfkill {
			compatible = "allwinner,sunxi-rfkill";
			status = "disabled";
		};

		addr_mgt: addr_mgt {
			compatible = "allwinner,sunxi-addr_mgt";
			status = "disabled";
		};

		btlpm: btlpm {
			compatible = "allwinner,sunxi-btlpm";
			status = "disabled";
		};

		/* audio dirver module -> audio codec */
		codec:codec@2030000 {
			#sound-dai-cells = <0>;
			compatible	= "allwinner,sunxi-snd-codec";
			reg		= <0x0 0x02030000 0x0 0x320>;
			resets		= <&ccu RST_BUS_AUDIO_CODEC>;
			clocks		= <&ccu CLK_AUDIO_CODEC>,
					  <&ccu CLK_AUDIO_CODEC_DAC_1X>,
					  <&ccu CLK_PLL_AUDIO0_4X>,
					  <&ccu CLK_PLL_AUDIO1_4X>;
			clock-names	= "clk_bus_audio",
					  "clk_audio_dac",
					  "clk_pll_audio0_4x",
					  "clk_pll_audio1_4x";
			status = "disabled";
		};

		codec_plat:codec_plat {
			#sound-dai-cells = <0>;
			compatible	= "allwinner,sunxi-snd-plat-aaudio";
			dac-txdata	= <0x02030020>;
			dmas		= <&dma0 7>;
			dma-names	= "tx";
			playback-cma	= <128>;
			tx-fifo-size	= <128>;
			status = "disabled";
		};

		codec_mach:codec_mach {
			compatible = "allwinner,sunxi-snd-mach";
			soundcard-mach,name		= "audiocodec";
			soundcard-mach,pin-switches	= "LINEOUTL", "SPK";
			soundcard-mach,routing		= "LINEOUTL", "LINEOUTLP_PIN",
							  "LINEOUTL", "LINEOUTLN_PIN",
							  "SPK", "LINEOUTLP_PIN",
							  "SPK", "LINEOUTLN_PIN";
			soundcard-mach,playback-only;
			status = "disabled";
			soundcard-mach,cpu {
				sound-dai = <&codec_plat>;
			};
			soundcard-mach,codec {
				sound-dai = <&codec>;
				soundcard-mach,pll-fs	= <1>;
			};
		};

		/* audio dirver module -> owa */
		owa_plat:owa_plat@2036000 {
			#sound-dai-cells = <0>;
			compatible	= "allwinner,sunxi-snd-plat-owa";
			reg		= <0x0 0x02036000 0x0 0x5C>;
			interrupts	= <GIC_SPI 23 IRQ_TYPE_LEVEL_HIGH>;
			resets		= <&ccu RST_BUS_OWA>;
			clocks		= <&ccu CLK_OWA>,
					  <&ccu CLK_OWA_TX>,
					  <&ccu CLK_OWA_RX>,
					  <&ccu CLK_PLL_AUDIO0_4X>,
					  <&ccu CLK_PLL_AUDIO1_4X>,
					  <&ccu CLK_PLL_PERI0_300M>;
			clock-names	= "clk_bus_owa",
					  "clk_owa_tx",
					  "clk_owa_rx",
					  "clk_pll_audio0_4x",
					  "clk_pll_audio1_4x",
					  "clk_pll_peri0_300";
			dmas		= <&dma0 2>, <&dma0 2>;
			dma-names	= "tx", "rx";
			playback-cma	= <128>;
			capture-cma	= <128>;
			tx-fifo-size	= <128>;
			rx-fifo-size	= <128>;
			status = "disabled";
		};

		owa_mach:owa_mach {
			compatible = "allwinner,sunxi-snd-mach";
			soundcard-mach,name = "sndowa";
			status = "disabled";
			soundcard-mach,cpu {
				sound-dai = <&owa_plat>;
			};
			soundcard-mach,codec {
			};
		};

		/* audio dirver module -> dmic */
		dmic_plat:dmic_plat@2031000 {
			#sound-dai-cells = <0>;
			compatible	= "allwinner,sunxi-snd-plat-dmic";
			reg		= <0x0 0x02031000 0x0 0x50>;
			resets		= <&ccu RST_BUS_DMIC>;
			clocks		= <&ccu CLK_BUS_DMIC>,
					  <&ccu CLK_DMIC>,
					  <&ccu CLK_PLL_AUDIO0_4X>,
					  <&ccu CLK_PLL_AUDIO1_4X>;
			clock-names	= "clk_bus_dmic",
					  "clk_dmic",
					  "clk_pll_audio0_4x",
					  "clk_pll_audio1_4x";
			dmas		= <&dma0 8>;
			dma-names	= "rx";
			capture-cma	= <128>;
			rx-fifo-size	= <128>;
			status = "disabled";
		};

		dmic_mach:dmic_mach{
			compatible = "allwinner,sunxi-snd-mach";
			soundcard-mach,name		= "snddmic";
			soundcard-mach,capture-only;
			status = "disabled";
			soundcard-mach,cpu {
				sound-dai = <&dmic_plat>;
			};
			soundcard-mach,codec {
			};
		};

		/* audio dirver module -> I2S/PCM */
		i2s0_plat:i2s0_plat@2032000 {
			#sound-dai-cells = <0>;
			compatible = "allwinner,sunxi-snd-plat-i2s";
			reg		= <0x0 0x02032000 0x0 0x7C>;
			resets		= <&ccu RST_BUS_I2SPCM0>;
			clocks		= <&ccu CLK_BUS_I2SPCM0>,
					  <&ccu CLK_I2SPCM0>,
					  <&ccu CLK_PLL_AUDIO0_4X>,
					  <&ccu CLK_PLL_AUDIO1_4X>;
			clock-names	= "clk_bus_i2s",
					  "clk_i2s",
					  "clk_pll_audio0_4x",
					  "clk_pll_audio1_4x";
			dmas		= <&dma0 3>, <&dma0 3>;
			dma-names	= "tx", "rx";
			playback-cma	= <128>;
			capture-cma	= <128>;
			tx-fifo-size	= <128>;
			rx-fifo-size	= <128>;
			status = "disabled";
		};

		i2s0_mach:i2s0_mach{
			compatible = "allwinner,sunxi-snd-mach";
			soundcard-mach,name		= "sndi2s0";
			soundcard-mach,format		= "i2s";
			soundcard-mach,slot-num		= <2>;
			soundcard-mach,slot-width	= <32>;
			status = "disabled";
			soundcard-mach,cpu {
				sound-dai = <&i2s0_plat>;
			};
			soundcard-mach,codec {
			};
		};

		i2s1_plat:i2s1_plat@2033000 {
			#sound-dai-cells = <0>;
			compatible = "allwinner,sunxi-snd-plat-i2s";
			reg		= <0x0 0x02033000 0x0 0x7C>;
			resets		= <&ccu RST_BUS_I2SPCM1>;
			clocks		= <&ccu CLK_BUS_I2SPCM1>,
					  <&ccu CLK_I2SPCM1>,
					  <&ccu CLK_PLL_AUDIO0_4X>,
					  <&ccu CLK_PLL_AUDIO1_4X>;
			clock-names	= "clk_bus_i2s",
					  "clk_i2s",
					  "clk_pll_audio0_4x",
					  "clk_pll_audio1_4x";
			dmas		= <&dma0 4>, <&dma0 4>;
			dma-names	= "tx", "rx";
			playback-cma	= <128>;
			capture-cma	= <128>;
			tx-fifo-size	= <128>;
			rx-fifo-size	= <128>;
			status = "disabled";
		};

		i2s1_mach:i2s1_mach{
			compatible = "allwinner,sunxi-snd-mach";
			soundcard-mach,name		= "sndi2s1";
			soundcard-mach,format		= "i2s";
			soundcard-mach,slot-num		= <2>;
			soundcard-mach,slot-width	= <32>;
			status = "disabled";
			soundcard-mach,cpu {
				sound-dai = <&i2s1_plat>;
			};
			soundcard-mach,codec {
			};
		};

		i2s2_plat:i2s2_plat@2034000 {
			#sound-dai-cells = <0>;
			compatible = "allwinner,sunxi-snd-plat-i2s";
			reg		= <0x0 0x02034000 0x0 0x7C>;
			resets		= <&ccu RST_BUS_I2SPCM2>;
			clocks		= <&ccu CLK_BUS_I2SPCM2>,
					  <&ccu CLK_I2SPCM2>,
					  <&ccu CLK_PLL_AUDIO0_4X>,
					  <&ccu CLK_PLL_AUDIO1_4X>;
			clock-names	= "clk_bus_i2s",
					  "clk_i2s",
					  "clk_pll_audio0_4x",
					  "clk_pll_audio1_4x";
			dmas		= <&dma0 5>, <&dma0 5>;
			dma-names	= "tx", "rx";
			playback-cma	= <128>;
			capture-cma	= <128>;
			tx-fifo-size	= <128>;
			rx-fifo-size	= <128>;
			status = "disabled";
		};

		i2s2_mach:i2s2_mach{
			compatible = "allwinner,sunxi-snd-mach";
			soundcard-mach,name		= "sndi2s2";
			soundcard-mach,format		= "i2s";
			soundcard-mach,slot-num		= <2>;
			soundcard-mach,slot-width	= <32>;
			status = "disabled";
			soundcard-mach,cpu {
				sound-dai = <&i2s2_plat>;
			};
			soundcard-mach,codec {
			};
		};

		i2s3_plat:i2s3_plat@2035000 {
			#sound-dai-cells = <0>;
			compatible = "allwinner,sunxi-snd-plat-i2s";
			reg		= <0x0 0x02035000 0x0 0x7C>;
			resets		= <&ccu RST_BUS_I2SPCM3>;
			clocks		= <&ccu CLK_BUS_I2SPCM3>,
					  <&ccu CLK_I2SPCM3>,
					  <&ccu CLK_PLL_AUDIO0_4X>,
					  <&ccu CLK_PLL_AUDIO1_4X>;
			clock-names	= "clk_bus_i2s",
					  "clk_i2s",
					  "clk_pll_audio0_4x",
					  "clk_pll_audio1_4x";
			dmas		= <&dma0 6>, <&dma0 6>;
			dma-names	= "tx", "rx";
			playback-cma	= <128>;
			capture-cma	= <128>;
			tx-fifo-size	= <128>;
			rx-fifo-size	= <128>;
			status = "disabled";
		};

		i2s3_mach:i2s3_mach{
			compatible = "allwinner,sunxi-snd-mach";
			soundcard-mach,name		= "sndi2s3";
			soundcard-mach,format		= "i2s";
			soundcard-mach,slot-num		= <2>;
			soundcard-mach,slot-width	= <32>;
			status = "disabled";
			soundcard-mach,cpu {
				sound-dai = <&i2s3_plat>;
			};
			soundcard-mach,codec {
			};
		};


		sid@3006000 {
			compatible = "allwinner,sunxi-sid";
			reg = <0x0 0x03006000 0 0x1000>;
			#address-cells = <1>;
			#size-cells = <1>;
			non-secure-maxoffset = <0x80>;
			non-secure-maxlen = <0x20>;

			secure_status {
				reg = <0x0 0>;
				offset = <0xa0>;
				size = <0x4>;
			};
			chipid {
				reg = <0x0 0>;
				offset = <0x200>;
				size = <0x10>;
			};
			rotpk {
				reg = <0x0 0>;
				offset = <0x140>;
				size = <0x20>;
			};
			ecc {
				offset = <0x240>;
				shift = <0x14>;
				mask = <0x1>;
			};
		};

		sram_ctrl: sram_ctrl@3000000 {
			compatible = "allwinner,sram_ctrl";
			reg = <0x0 0x03000000 0 0x184>;
			soc_ver {
				offset = <0x24>;
				mask = <0x7>;
				shift = <0>;
			};
		};

		nsi0: nsi-controller@2020000 {
			compatible = "allwinner,sunxi-nsi-v2";
			interrupts = <GIC_SPI 43 IRQ_TYPE_LEVEL_HIGH>;
			reg = <0x0 0x02020000 0x0 0x10000>;
			clocks = <&ccu CLK_PLL_DDR>, <&ccu CLK_MBUS>, <&ccu CLK_LBC>,
				<&ccu CLK_NSI>, <&ccu CLK_PLL_DDR>,
				<&ccu CLK_GIC>, <&ccu CLK_AHB>,
				<&ccu CLK_SERDES_AXI>, <&ccu CLK_GMAC_NSI>, <&ccu CLK_DRAM>;
			clock-names = "pll", "bus", "lbc",
					"nsi", "nsi-p",
					"gic", "ahb", "serdes", "gmac", "dram";
			resets = <&ccu RST_BUS_NSI>, <&ccu RST_BUS_NSI_CFG>;
			reset-names = "bus_nsi", "bus_nsi_cfg";
			clock-frequency = <600000000>, <600000000>;
			#nsi-cells = <1>;
			support-ecc = <1>;
			ra_pmu_data_unit = <64>;
			clk_path_type = <1>;
			topology_type = <2>;
			channel_type = <1>;
			master_clks = <0 9>, <1 5>, <2 1>, <3 1>, <4 1>, <5 1>, <6 1>, <7 3>, <8 1>, <9 7>,
					<10 1>, <11 3>, <12 2>, <13 8>, <14 3>, <15 3>, <16 1>, <17 3>, <18 3>, <19 6>,
					<20 6>, <21 6>, <22 6>, <23 6>, <24 6>, <25 6>;

			iommu {
				id = <6>;
				mode = <0>;
				pri = <3>;
				select = <1>;
			};

			de {
				id = <4>;
				mode = <0>;
				pri = <2>;
				select = <1>;
			};

			ve {
				id = <5>;
				mode = <0>;
				pri = <2>;
				select = <1>;
			};

			isp {
				id = <2>;
				mode = <0>;
				pri = <2>;
				select = <1>;
			};

			csi {
				id = <3>;
				mode = <0>;
				pri = <2>;
				select = <1>;
			};
		};

		g2d: g2d@5440000 {
			compatible = "allwinner,sunxi-g2d";
			reg = <0x0 0x05440000 0x0 0x30000>;
			interrupts = <GIC_SPI 143 IRQ_TYPE_LEVEL_HIGH>;
			clocks = <&ccu CLK_BUS_G2D>, <&ccu CLK_G2D>,
				<&ccu CLK_AHB_VID_OUT_GATE>, <&ccu CLK_MBUS_VO_SYS_GATE>;
			clock-names = "bus", "g2d", "vo", "mbus_vo";
			resets = <&ccu RST_BUS_G2D>;
			iommus = <&mmu_aw 4 1>;
			power-domains = <&pd MR536_PCK_VO>;
			power-domain-names = "pd1_vo0";
			assigned-clocks = <&ccu CLK_G2D>;
			assigned-clock-rates = <300000000>;
		};

		vind0: vind@5800800 {
			compatible = "allwinner,sunxi-vin-media", "simple-bus";
			#address-cells = <2>;
			#size-cells = <2>;
			ranges;
			device_id = <0>;
			csi_top = <450000000>;
			csi_isp = <320000000>;
			reg = <0x0 0x05800800 0x0 0x200>,
				<0x0 0x05800000 0x0 0x800>,
				<0x0 0x05810000 0x0 0x100>;
			interrupts = <GIC_SPI 139 IRQ_TYPE_LEVEL_HIGH>;
			clocks = <&ccu CLK_CSI>, <&ccu CLK_PLL_VIDEO1_4X>,
				<&ccu CLK_CSI_MASTER0>, <&dcxo24M>, <&ccu CLK_PLL_VIDEO0_4X>,
				<&ccu CLK_CSI_MASTER1>, <&dcxo24M>, <&ccu CLK_PLL_VIDEO0_4X>,
				<&ccu CLK_CSI_MASTER2>, <&dcxo24M>, <&ccu CLK_PLL_VIDEO0_4X>,
				<&ccu CLK_CSI_MASTER3>, <&dcxo24M>, <&ccu CLK_PLL_VIDEO0_4X>,
				<&ccu CLK_ISP>, <&ccu CLK_PLL_VIDEO0_4X>,
				<&ccu CLK_BUS_CSI>, <&ccu CLK_MBUS_CSI_GATE>, <&ccu CLK_MBUS_ISP_GATE>, <&ccu CLK_BUS_ISP>,
				<&ccu CLK_AHB_VID_IN_GATE>, <&ccu CLK_MBUS_VID_IN_GATE>;
			clock-names = "csi_top", "csi_top_src",
						"csi_mclk0", "csi_mclk0_24m", "csi_mclk0_pll",
						"csi_mclk1", "csi_mclk1_24m", "csi_mclk1_pll",
						"csi_mclk2", "csi_mclk2_24m", "csi_mclk2_pll",
						"csi_mclk3", "csi_mclk3_24m", "csi_mclk3_pll",
						"csi_isp", "csi_isp_src",
						"csi_bus", "csi_mbus", "csi_isp_mbus", "isp_bus",
						"vid_in_ahb", "vid_in_mbus";
			resets = <&ccu RST_BUS_CSI>, <&ccu RST_BUS_ISP>;
			reset-names = "csi_ret", "isp_ret";
			pinctrl-names = "mclk0-default", "mclk0-sleep", "mclk1-default", "mclk1-sleep",
							"mclk2-default", "mclk2-sleep", "mclk3-default", "mclk3-sleep";
			pinctrl-0 = <&csi_mclk0_pins_a>;
			pinctrl-1 = <&csi_mclk0_pins_b>;
			pinctrl-2 = <&csi_mclk1_pins_a>;
			pinctrl-3 = <&csi_mclk1_pins_b>;
			pinctrl-4 = <&csi_mclk2_pins_a>;
			pinctrl-5 = <&csi_mclk2_pins_b>;
			pinctrl-6 = <&csi_mclk3_pins_a>;
			pinctrl-7 = <&csi_mclk3_pins_b>;
			power-domains = <&pd MR536_PCK_VI>;
			dram_dfs_time = <>;
			status = "disabled";

			csi0: csi@5820000 {
				compatible = "allwinner,sunxi-csi";
				reg = <0x0 0x05820000 0x0 0x1000>;
				interrupts = <GIC_SPI 130 IRQ_TYPE_LEVEL_HIGH>;
				device_id = <0>;
				status = "disabled";
			};
			csi1: csi@5821000 {
				compatible = "allwinner,sunxi-csi";
				reg = <0x0 0x05821000 0x0 0x1000>;
				interrupts = <GIC_SPI 131 IRQ_TYPE_LEVEL_HIGH>;
				device_id = <1>;
				status = "disabled";
			};
			csi2: csi@5822000 {
				compatible = "allwinner,sunxi-csi";
				reg = <0x0 0x05822000 0x0 0x1000>;
				interrupts = <GIC_SPI 132 IRQ_TYPE_LEVEL_HIGH>;
				device_id = <2>;
				status = "disabled";
			};
			csi3: csi@5823000 {
				compatible = "allwinner,sunxi-csi";
				reg = <0x0 0x05823000 0x0 0x1000>;
				interrupts = <GIC_SPI 147 IRQ_TYPE_LEVEL_HIGH>;
				pinctrl-names = "default","sleep";
				pinctrl-0 = <&ncsi_bt656_pins_a>;
				pinctrl-1 = <&ncsi_bt656_pins_b>;
				device_id = <3>;
				status = "disabled";
			};
			mipi0: mipi@5810100 {
				compatible = "allwinner,sunxi-mipi";
				reg = <0x0 0x05810100 0x0 0x100>,
					<0x0 0x05811000 0x0 0x400>;
				interrupts = <GIC_SPI 137 IRQ_TYPE_LEVEL_HIGH>;
				pinctrl-names = "mipi0-default","mipi0-sleep",
						"mipi1-4lane-default","mipi1-4lane-sleep";
				pinctrl-0 = <&mipia_pins_a>;
				pinctrl-1 = <&mipia_pins_b>;
				pinctrl-2 = <&mipib_4lane_pins_a>;
				pinctrl-3 = <&mipib_4lane_pins_b>;
				device_id = <0>;
				status = "disabled";
			};
			mipi1: mipi@5810200 {
				compatible = "allwinner,sunxi-mipi";
				reg = <0x0 0x05810200 0x0 0x100>,
					<0x0 0x05811400 0x0 0x400>;
				pinctrl-names = "mipi1-default","mipi1-sleep";
				pinctrl-0 = <&mipib_pins_a>;
				pinctrl-1 = <&mipib_pins_b>;
				device_id = <1>;
				status = "disabled";
			};
			mipi2: mipi@5810300 {
				compatible = "allwinner,sunxi-mipi";
				reg = <0x0 0x05810300 0x0 0x100>,
					<0x0 0x05811800 0x0 0x400>;
				pinctrl-names = "mipi2-default","mipi2-sleep",
						"mipi3-4lane-default","mipi3-4lane-sleep";
				pinctrl-0 = <&mipic_pins_a>;
				pinctrl-1 = <&mipic_pins_b>;
				pinctrl-2 = <&mipid_4lane_pins_a>;
				pinctrl-3 = <&mipid_4lane_pins_b>;
				device_id = <2>;
				status = "disabled";
			};
			mipi3: mipi@5810400 {
				compatible = "allwinner,sunxi-mipi";
				reg = <0x0 0x05810400 0x0 0x100>,
					<0x0 0x05811C00 0x0 0x400>;
				pinctrl-names = "mipi3-default","mipi3-sleep";
				pinctrl-0 = <&mipid_pins_a>;
				pinctrl-1 = <&mipid_pins_b>;
				device_id = <3>;
				status = "disabled";
			};
			tdm0: tdm@5908000 {
				compatible = "allwinner,sunxi-tdm";
				reg = <0x0 0x05908000 0x0 0x340>;
				interrupts = <GIC_SPI 138 IRQ_TYPE_LEVEL_HIGH>;
				work_mode = <0x0>;
				device_id = <0>;
				iommus = <&mmu_aw 0 0>;
				status = "disabled";
			};
			isp00:isp@5900000 {
				compatible = "allwinner,sunxi-isp";
				reg = <0x0 0x05900000 0x0 0x1300>;
				interrupts = <GIC_SPI 133 IRQ_TYPE_LEVEL_HIGH>;
				work_mode = <0x0>;
				device_id = <0>;
				iommus = <&mmu_aw 0 0>;
				status = "disabled";
			};
			isp01:isp@58ffffc {
				compatible = "allwinner,sunxi-isp";
				reg = <0x0 0x058ffffc 0x0 0x1304>;
				interrupts = <GIC_SPI 134 IRQ_TYPE_LEVEL_HIGH>;
				work_mode = <0xff>;
				device_id = <1>;
				iommus = <&mmu_aw 0 0>;
				status = "disabled";
			};
			isp02:isp@58ffff8 {
				compatible = "allwinner,sunxi-isp";
				reg = <0x0 0x058ffff8 0x0 0x1308>;
				interrupts = <GIC_SPI 135 IRQ_TYPE_LEVEL_HIGH>;
				work_mode = <0xff>;
				device_id = <2>;
				iommus = <&mmu_aw 0 0>;
				status = "disabled";
			};
			isp03:isp@58ffff4 {
				compatible = "allwinner,sunxi-isp";
				reg = <0x0 0x058ffff4 0x0 0x130c>;
				interrupts = <GIC_SPI 136 IRQ_TYPE_LEVEL_HIGH>;
				work_mode = <0xff>;
				device_id = <3>;
				iommus = <&mmu_aw 0 0>;
				status = "disabled";
			};
			isp10:isp@4 {
				compatible = "allwinner,sunxi-isp";
				device_id = <4>;
				iommus = <&mmu_aw 0 0>;
				status = "disabled";
			};
			isp20:isp@5 {
				compatible = "allwinner,sunxi-isp";
				device_id = <5>;
				iommus = <&mmu_aw 0 0>;
				status = "disabled";
			};
			isp30:isp@6 {
				compatible = "allwinner,sunxi-isp";
				device_id = <6>;
				iommus = <&mmu_aw 0 0>;
				status = "disabled";
			};
			scaler00:scaler@5910000 {
				compatible = "allwinner,sunxi-scaler";
				reg = <0x0 0x05910000 0x0 0x400>;
				interrupts = <GIC_SPI 126 IRQ_TYPE_LEVEL_HIGH>;
				work_mode = <0x0>;
				device_id = <0>;
				iommus = <&mmu_aw 1 0>;
				status = "disabled";
			};
			scaler01:scaler@590fffc {
				compatible = "allwinner,sunxi-scaler";
				reg = <0x0 0x0590fffc 0x0 0x404>;
				work_mode = <0xff>;
				device_id = <1>;
				iommus = <&mmu_aw 1 0>;
				status = "disabled";
			};
			scaler02:scaler@590fff8 {
				compatible = "allwinner,sunxi-scaler";
				reg = <0x0 0x0590fff8 0x0 0x408>;
				work_mode = <0xff>;
				device_id = <2>;
				iommus = <&mmu_aw 1 0>;
				status = "disabled";
			};
			scaler03:scaler@590fff4 {
				compatible = "allwinner,sunxi-scaler";
				reg = <0x0 0x0590fff4 0x0 0x40c>;
				work_mode = <0xff>;
				device_id = <3>;
				iommus = <&mmu_aw 1 0>;
				status = "disabled";
			};
			scaler10:scaler@5910400 {
				compatible = "allwinner,sunxi-scaler";
				reg = <0x0 0x05910400 0x0 0x400>;
				interrupts = <GIC_SPI 127 IRQ_TYPE_LEVEL_HIGH>;
				work_mode = <0x0>;
				device_id = <4>;
				iommus = <&mmu_aw 1 0>;
				status = "disabled";
			};
			scaler11:scaler@59103fc {
				compatible = "allwinner,sunxi-scaler";
				reg = <0x0 0x059103fc 0x0 0x404>;
				work_mode = <0xff>;
				device_id = <5>;
				iommus = <&mmu_aw 1 0>;
				status = "disabled";
			};
			scaler12:scaler@59103f8 {
				compatible = "allwinner,sunxi-scaler";
				reg = <0x0 0x059103f8 0x0 0x408>;
				work_mode = <0xff>;
				device_id = <6>;
				iommus = <&mmu_aw 1 0>;
				status = "disabled";
			};
			scaler13:scaler@59103f4 {
				compatible = "allwinner,sunxi-scaler";
				reg = <0x0 0x059103f4 0x0 0x40c>;
				work_mode = <0xff>;
				device_id = <7>;
				iommus = <&mmu_aw 1 0>;
				status = "disabled";
			};
			scaler20:scaler@5910800 {
				compatible = "allwinner,sunxi-scaler";
				reg = <0x0 0x05910800 0x0 0x400>;
				interrupts = <GIC_SPI 128 IRQ_TYPE_LEVEL_HIGH>;
				work_mode = <0x0>;
				device_id = <8>;
				iommus = <&mmu_aw 1 0>;
				status = "disabled";
			};
			scaler21:scaler@59107fc {
				compatible = "allwinner,sunxi-scaler";
				reg = <0x0 0x059107fc 0x0 0x404>;
				work_mode = <0xff>;
				device_id = <9>;
				iommus = <&mmu_aw 1 0>;
				status = "disabled";
			};
			scaler22:scaler@59107f8 {
				compatible = "allwinner,sunxi-scaler";
				reg = <0x0 0x059107f8 0x0 0x408>;
				work_mode = <0xff>;
				device_id = <10>;
				iommus = <&mmu_aw 1 0>;
				status = "disabled";
			};
			scaler23:scaler@59107f4 {
				compatible = "allwinner,sunxi-scaler";
				reg = <0x0 0x059107f4 0x0 0x40c>;
				work_mode = <0xff>;
				device_id = <11>;
				iommus = <&mmu_aw 1 0>;
				status = "disabled";
			};
			scaler30:scaler@5910c00 {
				compatible = "allwinner,sunxi-scaler";
				reg = <0x0 0x05910c00 0x0 0x400>;
				interrupts = <GIC_SPI 129 IRQ_TYPE_LEVEL_HIGH>;
				work_mode = <0x0>;
				device_id = <12>;
				iommus = <&mmu_aw 1 0>;
				status = "disabled";
			};
			scaler31:scaler@5910bfc {
				compatible = "allwinner,sunxi-scaler";
				reg = <0x0 0x05910bfc 0x0 0x404>;
				work_mode = <0xff>;
				device_id = <13>;
				iommus = <&mmu_aw 1 0>;
				status = "disabled";
			};
			scaler32:scaler@5910bf8 {
				compatible = "allwinner,sunxi-scaler";
				reg = <0x0 0x05910bf8 0x0 0x408>;
				work_mode = <0xff>;
				device_id = <14>;
				iommus = <&mmu_aw 1 0>;
				status = "disabled";
			};
			scaler33:scaler@5910bf4 {
				compatible = "allwinner,sunxi-scaler";
				reg = <0x0 0x05910bf4 0x0 0x40c>;
				work_mode = <0xff>;
				device_id = <15>;
				iommus = <&mmu_aw 1 0>;
				status = "disabled";
			};
			actuator0: actuator@2108180 {
				compatible = "allwinner,sunxi-actuator";
				device_type = "actuator0";
				reg = <0x0 0x02108180 0x0 0x10>;
				actuator0_name = "ad5820_act";
				actuator0_slave = <0x18>;
				actuator0_af_pwdn = <>;
				actuator0_afvdd = "afvcc-csi";
				actuator0_afvdd_vol = <2800000>;
				status = "disabled";
			};
			flash0: flash@2108190 {
				device_type = "flash0";
				compatible = "allwinner,sunxi-flash";
				reg = <0x0 0x02108190 0x0 0x10>;
				flash0_type = <2>;
				flash0_en = <>;
				flash0_mode = <>;
				flash0_flvdd = "";
				flash0_flvdd_vol = <>;
				device_id = <0>;
				status = "disabled";
			};
			sensor0: sensor@5812000 {
				reg = <0x0 0x05812000 0x0 0x10>;
				device_type = "sensor0";
				compatible = "allwinner,sunxi-sensor";
				sensor0_mname = "ov5640";
				sensor0_twi_cci_id = <2>;
				sensor0_twi_addr = <0x78>;
				sensor0_mclk_id = <0>;
				sensor0_pos = "rear";
				sensor0_isp_used = <0>;
				sensor0_fmt = <0>;
				sensor0_stby_mode = <0>;
				sensor0_vflip = <0>;
				sensor0_hflip = <0>;
				sensor0_iovdd-supply = <>;
				sensor0_iovdd_vol = <>;
				sensor0_avdd-supply = <>;
				sensor0_avdd_vol = <>;
				sensor0_dvdd-supply = <>;
				sensor0_dvdd_vol = <>;
				sensor0_power_en = <>;
				sensor0_reset = <>;
				sensor0_pwdn = <>;
				sensor0_sm_vs = <>;
				flash_handle = <&flash0>;
				act_handle = <&actuator0>;
				device_id = <0>;
				status	= "disabled";
			};
			sensor1: sensor@5812010 {
				reg = <0x0 0x05812010 0x0 0x10>;
				device_type = "sensor1";
				compatible = "allwinner,sunxi-sensor";
				sensor1_mname = "ov5647";
				sensor1_twi_cci_id = <3>;
				sensor1_twi_addr = <0x6c>;
				sensor1_mclk_id = <1>;
				sensor1_pos = "front";
				sensor1_isp_used = <0>;
				sensor1_fmt = <0>;
				sensor1_stby_mode = <0>;
				sensor1_vflip = <0>;
				sensor1_hflip = <0>;
				sensor1_iovdd-supply = <>;
				sensor1_iovdd_vol = <>;
				sensor1_avdd-supply = <>;
				sensor1_avdd_vol = <>;
				sensor1_dvdd-supply = <>;
				sensor1_dvdd_vol = <>;
				sensor1_power_en = <>;
				sensor1_reset = <>;
				sensor1_pwdn = <>;
				sensor1_sm_vs = <>;
				flash_handle = <>;
				act_handle = <>;
				device_id = <1>;
				status	= "disabled";
			};
			sensor2: sensor@5812020 {
				reg = <0x0 0x05812020 0x0 0x10>;
				device_type = "sensor2";
				compatible = "allwinner,sunxi-sensor";
				sensor2_mname = "imx386_mipi";
				sensor2_twi_cci_id = <3>;
				sensor2_twi_addr = <0x6c>;
				sensor2_mclk_id = <1>;
				sensor2_pos = "rear";
				sensor2_isp_used = <0>;
				sensor2_fmt = <0>;
				sensor2_stby_mode = <0>;
				sensor2_vflip = <0>;
				sensor2_hflip = <0>;
				sensor2_iovdd-supply = <>;
				sensor2_iovdd_vol = <>;
				sensor2_avdd-supply = <>;
				sensor2_avdd_vol = <>;
				sensor2_dvdd-supply = <>;
				sensor2_dvdd_vol = <>;
				sensor2_power_en = <>;
				sensor2_reset = <>;
				sensor2_pwdn = <>;
				sensor2_sm_vs = <>;
				flash_handle = <>;
				act_handle = <>;
				device_id = <2>;
				status= "disabled";
			};
			sensor3: sensor@5812030 {
				reg = <0x0 0x05812030 0x0 0x10>;
				device_type = "sensor3";
				compatible = "allwinner,sunxi-sensor";
				sensor3_mname = "imx317_mipi";
				sensor3_twi_cci_id = <3>;
				sensor3_twi_addr = <0x6c>;
				sensor3_mclk_id = <1>;
				sensor3_pos = "rear";
				sensor3_isp_used = <0>;
				sensor3_fmt = <0>;
				sensor3_stby_mode = <0>;
				sensor3_vflip = <0>;
				sensor3_hflip = <0>;
				sensor3_iovdd-supply = <>;
				sensor3_iovdd_vol = <>;
				sensor3_avdd-supply = <>;
				sensor3_avdd_vol = <>;
				sensor3_dvdd-supply = <>;
				sensor3_dvdd_vol = <>;
				sensor3_power_en = <>;
				sensor3_reset = <>;
				sensor3_pwdn = <>;
				sensor3_sm_vs = <>;
				flash_handle = <>;
				act_handle = <>;
				device_id = <2>;
				status= "disabled";
			};
			sensor_list0:sensor_list@200b820 {
				reg = <0x0 0x0200b820 0x0 0x10>;
				device_type = "sensor_list0";
				compatible = "allwinner,sunxi-sensor-list";
				csi_sel = <0>;
				sensor00_mname = "gc5035_mipi";
				sensor00_twi_addr = <0x6c>;
				sensor00_type = <1>;
				sensor00_hflip =  <0>;
				sensor00_vflip = <0>;
				sensor00_act_used = <1>;
				sensor00_act_name = "";
				sensor00_act_twi_addr = <>;
				sensor01_mname = "ov5675_mipi";
				sensor01_twi_addr = <0x6c>;
				sensor01_type = <1>;
				sensor01_hflip =  <0>;
				sensor01_vflip = <0>;
				sensor01_act_used = <1>;
				sensor01_act_name = "dw9714_act";
				sensor01_act_twi_addr = <0x18>;
				sensor02_mname = "sp5409_mipi";
				sensor02_twi_addr = <0x78>;
				sensor02_type = <1>;
				sensor02_hflip =  <0>;
				sensor02_vflip = <0>;
				sensor02_act_used = <0>;
				sensor02_act_name = "dw9714_act";
				sensor02_act_twi_addr = <0x18>;
				device_id = <0>;
				status	= "disabled";
			};
			sensor_list1:sensor_list@200b830 {
				reg = <0x0 0x0200b830 0x0 0x10>;
				device_type = "sensor_list1";
				compatible = "allwinner,sunxi-sensor-list";
				csi_sel = <0>;
				sensor10_mname = "gc02m2_mipi";
				sensor10_twi_addr = <0x20>;
				sensor10_type = <1>;
				sensor10_hflip =  <0>;
				sensor10_vflip = <0>;
				sensor10_act_used = <1>;
				sensor10_act_name = "dw9714_act";
				sensor10_act_twi_addr = <0x18>;
				sensor11_mname = "ov02a10_mipi";
				sensor11_twi_addr = <0x7a>;
				sensor11_type = <1>;
				sensor11_hflip =  <1>;
				sensor11_vflip = <0>;
				sensor11_act_used = <0>;
				sensor11_act_name = "";
				sensor11_act_twi_addr = <>;
				sensor12_mname = "gc030a_mipi";
				sensor12_twi_addr = <0x42>;
				sensor12_type = <1>;
				sensor12_hflip =  <0>;
				sensor12_vflip = <0>;
				sensor12_act_used = <0>;
				sensor12_act_name = "";
				sensor12_act_twi_addr = <>;
				device_id = <1>;
				status	= "disabled";
			};
			vinc00:vinc@5830000 {
				device_type = "vinc0";
				compatible = "allwinner,sunxi-vin-core";
				reg = <0x0 0x05830000 0x0 0x1000>;
				interrupts = <GIC_SPI 122 IRQ_TYPE_LEVEL_HIGH>;
				vinc0_csi_sel = <3>;
				vinc0_mipi_sel = <0xff>;
				vinc0_isp_sel = <0>;
				vinc0_isp_tx_ch = <0>;
				vinc0_tdm_rx_sel = <0>;
				vinc0_rear_sensor_sel = <0>;
				vinc0_front_sensor_sel = <0>;
				vinc0_sensor_list = <0>;
				device_id = <0>;
				work_mode = <0x0>;
				iommus = <&mmu_aw 1 0>;
				status = "disabled";
			};

			vinc01:vinc@582fffc {
				device_type = "vinc1";
				compatible = "allwinner,sunxi-vin-core";
				reg = <0x0 0x0582fffc 0x0 0x1004>;
				vinc1_csi_sel = <2>;
				vinc1_mipi_sel = <0xff>;
				vinc1_isp_sel = <1>;
				vinc1_isp_tx_ch = <1>;
				vinc1_tdm_rx_sel = <1>;
				vinc1_rear_sensor_sel = <0>;
				vinc1_front_sensor_sel = <0>;
				vinc1_sensor_list = <0>;
				device_id = <1>;
				work_mode = <0xff>;
				iommus = <&mmu_aw 1 0>;
				status = "disabled";
			};
			vinc02:vinc@582fff8 {
				device_type = "vinc2";
				compatible = "allwinner,sunxi-vin-core";
				reg = <0x0 0x0582fff8 0x0 0x1008>;
				vinc2_csi_sel = <2>;
				vinc2_mipi_sel = <0xff>;
				vinc2_isp_sel = <2>;
				vinc2_isp_tx_ch = <2>;
				vinc2_tdm_rx_sel = <2>;
				vinc2_rear_sensor_sel = <0>;
				vinc2_front_sensor_sel = <0>;
				vinc2_sensor_list = <0>;
				device_id = <2>;
				work_mode = <0xff>;
				iommus = <&mmu_aw 1 0>;
				status = "disabled";
			};

			vinc03:vinc@582fff4 {
				device_type = "vinc3";
				compatible = "allwinner,sunxi-vin-core";
				reg = <0x0 0x0582fff4 0x0 0x100c>;
				vinc3_csi_sel = <0>;
				vinc3_mipi_sel = <0xff>;
				vinc3_isp_sel = <0>;
				vinc3_isp_tx_ch = <0>;
				vinc3_tdm_rx_sel = <0>;
				vinc3_rear_sensor_sel = <1>;
				vinc3_front_sensor_sel = <1>;
				vinc3_sensor_list = <0>;
				device_id = <3>;
				work_mode = <0xff>;
				iommus = <&mmu_aw 1 0>;
				status = "disabled";
			};

			vinc10:vinc@5831000 {
				device_type = "vinc4";
				compatible = "allwinner,sunxi-vin-core";
				reg = <0x0 0x05831000 0x0 0x1000>;
				interrupts = <GIC_SPI 123 IRQ_TYPE_LEVEL_HIGH>;
				vinc4_csi_sel = <3>;
				vinc4_mipi_sel = <0xff>;
				vinc4_isp_sel = <0>;
				vinc4_isp_tx_ch = <0>;
				vinc4_tdm_rx_sel = <0>;
				vinc4_rear_sensor_sel = <0>;
				vinc4_front_sensor_sel = <0>;
				vinc4_sensor_list = <0>;
				device_id = <4>;
				work_mode = <0x0>;
				iommus = <&mmu_aw 1 0>;
				status = "disabled";
			};

			vinc11:vinc@5830ffc {
				device_type = "vinc5";
				compatible = "allwinner,sunxi-vin-core";
				reg = <0x0 0x05830ffc 0x0 0x1004>;
				vinc5_csi_sel = <2>;
				vinc5_mipi_sel = <0xff>;
				vinc5_isp_sel = <1>;
				vinc5_isp_tx_ch = <1>;
				vinc5_tdm_rx_sel = <1>;
				vinc5_rear_sensor_sel = <0>;
				vinc5_front_sensor_sel = <0>;
				vinc5_sensor_list = <0>;
				device_id = <5>;
				work_mode = <0xff>;
				iommus = <&mmu_aw 1 0>;
				status = "disabled";
			};

			vinc12:vinc@5830ff8 {
				device_type = "vinc6";
				compatible = "allwinner,sunxi-vin-core";
				reg = <0x0 0x05830ff8 0x0 0x1008>;
				vinc6_csi_sel = <2>;
				vinc6_mipi_sel = <0xff>;
				vinc6_isp_sel = <0>;
				vinc6_isp_tx_ch = <0>;
				vinc6_tdm_rx_sel = <0>;
				vinc6_rear_sensor_sel = <0>;
				vinc6_front_sensor_sel = <0>;
				vinc6_sensor_list = <0>;
				device_id = <6>;
				work_mode = <0xff>;
				iommus = <&mmu_aw 1 0>;
				status = "disabled";
			};

			vinc13:vinc@5830ff4 {
				device_type = "vinc7";
				compatible = "allwinner,sunxi-vin-core";
				reg = <0x0 0x05830ff4 0x0 0x100c>;
				vinc7_csi_sel = <2>;
				vinc7_mipi_sel = <0xff>;
				vinc7_isp_sel = <0>;
				vinc7_isp_tx_ch = <0>;
				vinc7_tdm_rx_sel = <0>;
				vinc7_rear_sensor_sel = <0>;
				vinc7_front_sensor_sel = <0>;
				vinc7_sensor_list = <0>;
				device_id = <7>;
				work_mode = <0xff>;
				iommus = <&mmu_aw 1 0>;
				status = "disabled";
			};

			vinc20:vinc@5832000 {
				device_type = "vinc8";
				compatible = "allwinner,sunxi-vin-core";
				reg = <0x0 0x05832000 0x0 0x1000>;
				interrupts = <GIC_SPI 124 IRQ_TYPE_LEVEL_HIGH>;
				vinc8_csi_sel = <2>;
				vinc8_mipi_sel = <0xff>;
				vinc8_isp_sel = <4>;
				vinc8_isp_tx_ch = <3>;
				vinc8_tdm_rx_sel = <3>;
				vinc8_rear_sensor_sel = <0>;
				vinc8_front_sensor_sel = <0>;
				vinc8_sensor_list = <0>;
				device_id = <8>;
				work_mode = <0x0>;
				iommus = <&mmu_aw 1 0>;
				status = "disabled";
			};

			vinc21:vinc@5831ffc {
				device_type = "vinc9";
				compatible = "allwinner,sunxi-vin-core";
				reg = <0x0 0x05831ffc 0x0 0x1004>;
				vinc9_csi_sel = <2>;
				vinc9_mipi_sel = <0xff>;
				vinc9_isp_sel = <0>;
				vinc9_isp_tx_ch = <0>;
				vinc9_tdm_rx_sel = <0>;
				vinc9_rear_sensor_sel = <0>;
				vinc9_front_sensor_sel = <0>;
				vinc9_sensor_list = <0>;
				device_id = <9>;
				work_mode = <0xff>;
				iommus = <&mmu_aw 1 0>;
				status = "disabled";
			};

			vinc22:vinc@5831ff8 {
				device_type = "vinc10";
				compatible = "allwinner,sunxi-vin-core";
				reg = <0x0 0x05831ff8 0x0 0x1008>;
				vinc10_csi_sel = <2>;
				vinc10_mipi_sel = <0xff>;
				vinc10_isp_sel = <0>;
				vinc10_isp_tx_ch = <0>;
				vinc10_tdm_rx_sel = <0>;
				vinc10_rear_sensor_sel = <0>;
				vinc10_front_sensor_sel = <0>;
				vinc10_sensor_list = <0>;
				device_id = <10>;
				work_mode = <0xff>;
				iommus = <&mmu_aw 1 0>;
				status = "disabled";
			};

			vinc23:vinc@5831ff4 {
				device_type = "vinc11";
				compatible = "allwinner,sunxi-vin-core";
				reg = <0x0 0x05831ff4 0x0 0x100c>;
				vinc11_csi_sel = <2>;
				vinc11_mipi_sel = <0xff>;
				vinc11_isp_sel = <0>;
				vinc11_isp_tx_ch = <0>;
				vinc11_tdm_rx_sel = <0>;
				vinc11_rear_sensor_sel = <0>;
				vinc11_front_sensor_sel = <0>;
				vinc11_sensor_list = <0>;
				device_id = <11>;
				work_mode = <0xff>;
				iommus = <&mmu_aw 1 0>;
				status = "disabled";
			};

			vinc30:vinc@5833000 {
				device_type = "vinc12";
				compatible = "allwinner,sunxi-vin-core";
				reg = <0x0 0x05833000 0x0 0x1000>;
				interrupts = <GIC_SPI 125 IRQ_TYPE_LEVEL_HIGH>;
				vinc12_csi_sel = <2>;
				vinc12_mipi_sel = <0xff>;
				vinc12_isp_sel = <0>;
				vinc12_isp_tx_ch = <0>;
				vinc12_tdm_rx_sel = <0>;
				vinc12_rear_sensor_sel = <0>;
				vinc12_front_sensor_sel = <0>;
				vinc12_sensor_list = <0>;
				device_id = <12>;
				work_mode = <0x0>;
				iommus = <&mmu_aw 1 0>;
				status = "disabled";
			};

			vinc31:vinc@5832ffc {
				device_type = "vinc13";
				compatible = "allwinner,sunxi-vin-core";
				reg = <0x0 0x05832ffc 0x0 0x1004>;
				vinc13_csi_sel = <2>;
				vinc13_mipi_sel = <0xff>;
				vinc13_isp_sel = <0>;
				vinc13_isp_tx_ch = <0>;
				vinc13_tdm_rx_sel = <0>;
				vinc13_rear_sensor_sel = <0>;
				vinc13_front_sensor_sel = <0>;
				vinc13_sensor_list = <0>;
				device_id = <13>;
				work_mode = <0xff>;
				iommus = <&mmu_aw 1 0>;
				status = "disabled";
			};

			vinc32:vinc@5832ff8 {
				device_type = "vinc14";
				compatible = "allwinner,sunxi-vin-core";
				reg = <0x0 0x05832ff8 0x0 0x1008>;
				vinc14_csi_sel = <2>;
				vinc14_mipi_sel = <0xff>;
				vinc14_isp_sel = <0>;
				vinc14_isp_tx_ch = <0>;
				vinc14_tdm_rx_sel = <0>;
				vinc14_rear_sensor_sel = <0>;
				vinc14_front_sensor_sel = <0>;
				vinc14_sensor_list = <0>;
				device_id = <14>;
				work_mode = <0xff>;
				iommus = <&mmu_aw 1 0>;
				status = "disabled";
			};

			vinc33:vinc@5832ff4 {
				device_type = "vinc15";
				compatible = "allwinner,sunxi-vin-core";
				reg = <0x0 0x05832ff4 0x0 0x100c>;
				vinc15_csi_sel = <2>;
				vinc15_mipi_sel = <0xff>;
				vinc15_isp_sel = <0>;
				vinc15_isp_tx_ch = <0>;
				vinc15_tdm_rx_sel = <0>;
				vinc15_rear_sensor_sel = <0>;
				vinc15_front_sensor_sel = <0>;
				vinc15_sensor_list = <0>;
				device_id = <15>;
				work_mode = <0xff>;
				iommus = <&mmu_aw 1 0>;
				status = "disabled";
			};
		};
		ve: ve@1c0e000 {
			compatible = "allwinner,sunxi-cedar-ve";
			reg = <0x0 0x01c0e000 0x0 0x1000>,      /* ve */
				  <0x0 0x03000000 0x0 0x10>;        /* syscfg */
			interrupts = <GIC_SPI 120 IRQ_TYPE_LEVEL_HIGH>; /* VE0: 152-32 */
			clocks = <&ccu CLK_BUS_VE>,
					<&ccu CLK_VE>,
					<&ccu CLK_MBUS_VE_GATE>;
			clock-names = "bus_ve", "ve", "mbus_ve";
			resets = <&ccu RST_BUS_VE>;
			reset-names = "reset_ve";
			ve_top_reg_offset = <0x800>; /*should check with ve spec*/
			iommus = <&mmu_aw 2 1>;
			power-domains = <&pd MR536_PCK_VE>;
			status = "disabled";
		};

		lbc: lbc-controller@2810000 {
			compatible = "allwinner,sunxi-lbc";
			clock-frequency = <50000000>;
			reg = <0x0 0x02810000 0x0 0x1000>,
				  <0x0 0x10000000 0x0 0x8000000>;
			reg-names = "reg_addr", "data_addr";
			interrupts = <GIC_SPI 48 IRQ_TYPE_LEVEL_HIGH>;
			clocks = <&ccu CLK_PLL_PERI0_400M>, <&ccu CLK_PLL_PERI0_200M>,
					 <&ccu CLK_LBC_NSI_AHB>, <&ccu CLK_BUS_LBC>, <&ccu CLK_LBC>;
			clock-names = "lbc_pll", "lbc_nsi_pll", "lbc_nsi_ahb", "bus_lbc", "lbc";
			resets = <&ccu RST_BUS_LBC>;
			reset-names = "lbc_rst";
			reset-fpga-gpios = <&pio PA 7 GPIO_ACTIVE_LOW>;
			async-tx-fifo-size = "64";
			async-rx-fifo-size = "64";
			status = "disabled";
		};

		gmac_stmmac_axi_setup: stmmac-axi-config {
			snps,wr_osr_lmt = <0xf>;
			snps,rd_osr_lmt = <0xf>;
			snps,blen = <256 128 64 32 16 8 4>;
		};

		gmac_mtl_rx_setup: rx-queues-config {
			snps,rx-queues-to-use = <1>;
			queue0 {};
		};

		gmac_mtl_tx_setup: tx_queues-config {
			snps,tx-queues-to-use = <1>;
			queue0 {};
		};

		gmac0: ethernet@4500000 {
			compatible = "allwinner,sunxi-gmac-220", "snps,dwmac-5.10a";
			reg = <0x0 0x04500000 0x0 0x8000>,
				  <0x0 0x04508000 0x0 0x8000>;
			interrupts = <GIC_SPI 46 IRQ_TYPE_LEVEL_HIGH>;
			interrupt-names = "macirq";
			clocks = <&ccu CLK_GMAC0>, <&ccu CLK_MBUS_GMAC0_GATE>, <&ccu CLK_GMAC0_PHY>,
					<&ccu CLK_GMAC0_PTP>, <&ccu CLK_GMAC_NSI>;
			clock-names = "stmmaceth", "pclk", "phy", "ptp_ref", "nsi";
			assigned-clocks = <&ccu CLK_GMAC_NSI>, <&ccu CLK_GMAC0_PHY>;
			assigned-clock-parents = <&ccu CLK_PLL_PERI0_480M>;
			assigned-clock-rates = <480000000>, <25000000>;
			resets = <&ccu RST_BUS_GMAC0_AXI>, <&ccu RST_BUS_GMAC0>;
			reset-names = "stmmaceth", "ahb";
			phy-handle = <&gmac0_phy0>;
			status = "disabled";

			snps,fixed-burst;
			snps,axi-config = <&gmac_stmmac_axi_setup>;
			snps,mtl-rx-config = <&gmac_mtl_rx_setup>;
			snps,mtl-tx-config = <&gmac_mtl_tx_setup>;

			aw,rgmii-clk-ext;

			mdio0: mdio0@0 {
				compatible = "snps,dwmac-mdio";
				#address-cells = <1>;
				#size-cells = <0>;
				gmac0_phy0: ethernet-phy@1 {
					compatible = "ethernet-phy-ieee802.3-c22";
					reg = <0x1>;
					max-speed = <1000>;  /* Max speed capability */
					reset-gpios = <&pio PB 7 GPIO_ACTIVE_LOW>;
					/* PHY datasheet rst time */
					reset-assert-us = <10000>;
					reset-deassert-us = <150000>;
				};
			};
		};

		gmac1: ethernet@4510000 {
			compatible = "allwinner,sunxi-gmac-220", "snps,dwmac-5.10a";
			reg = <0x0 0x04510000 0x0 0x8000>,
				  <0x0 0x04518000 0x0 0x8000>;
			interrupts = <GIC_SPI 47 IRQ_TYPE_LEVEL_HIGH>;
			interrupt-names = "macirq";
			clocks = <&ccu CLK_GMAC1>, <&ccu CLK_MBUS_GMAC1_GATE>, <&ccu CLK_GMAC1_PHY>,
					<&ccu CLK_GMAC1_PTP>, <&ccu CLK_GMAC_NSI>;
			clock-names = "stmmaceth", "pclk", "phy", "ptp_ref", "nsi";
			assigned-clocks = <&ccu CLK_GMAC_NSI>, <&ccu CLK_GMAC1_PHY>;
			assigned-clock-parents = <&ccu CLK_PLL_PERI0_480M>;
			assigned-clock-rates = <480000000>, <25000000>;
			resets = <&ccu RST_BUS_GMAC1_AXI>, <&ccu RST_BUS_GMAC1>;
			reset-names = "stmmaceth", "ahb";
			phy-handle = <&gmac1_phy0>;
			status = "disabled";

			snps,fixed-burst;
			snps,axi-config = <&gmac_stmmac_axi_setup>;
			snps,mtl-rx-config = <&gmac_mtl_rx_setup>;
			snps,mtl-tx-config = <&gmac_mtl_tx_setup>;
			aw,rgmii-clk-ext;

			mdio1: mdio1@0 {
				compatible = "snps,dwmac-mdio";
				#address-cells = <1>;
				#size-cells = <0>;
				gmac1_phy0: ethernet-phy@1 {
					compatible = "ethernet-phy-ieee802.3-c22";
					reg = <0x1>;
					max-speed = <1000>;  /* Max speed capability */
					reset-gpios = <&pio PB 8 GPIO_ACTIVE_LOW>;
					/* PHY datasheet rst time */
					reset-assert-us = <10000>;
					reset-deassert-us = <150000>;
				};
			};
		};
	};

	soc2: soc@2 {
		compatible = "simple-bus";
		#address-cells = <2>;
		#size-cells = <2>;
		ranges;
		device_type = "guest-soc";
		kylo-os-id = <2>;

		pio1: pinctrl@1 {
			//#address-cells = <1>;
			//#size-cells = <0>;
			compatible = "allwinner,sun55iw6-pinctrl";
			reg = <0x0 0x03604000 0x0 0x600>;
#if 0
			interrupts = <GIC_SPI 67 IRQ_TYPE_LEVEL_HIGH>,
							 <GIC_SPI 69 IRQ_TYPE_LEVEL_HIGH>,
							 <GIC_SPI 71 IRQ_TYPE_LEVEL_HIGH>,
							 <GIC_SPI 73 IRQ_TYPE_LEVEL_HIGH>,
							 <GIC_SPI 75 IRQ_TYPE_LEVEL_HIGH>,
							 <GIC_SPI 77 IRQ_TYPE_LEVEL_HIGH>,
							 <GIC_SPI 79 IRQ_TYPE_LEVEL_HIGH>,
							 <GIC_SPI 81 IRQ_TYPE_LEVEL_HIGH>,
							 <GIC_SPI 83 IRQ_TYPE_LEVEL_HIGH>,
							 <GIC_SPI 85 IRQ_TYPE_LEVEL_HIGH>,
							 <GIC_SPI 140 IRQ_TYPE_LEVEL_HIGH>;
#endif
			clocks = <&ccu CLK_APB1>, <&dcxo24M>, <&rtc_ccu CLK_OSC32K>;
			clock-names = "apb", "hosc", "losc";
			gpio-controller;
			#gpio-cells = <3>;
			interrupt-controller;
			#interrupt-cells = <3>;
		};

		r_pio1: pinctrl@11 {
			#address-cells = <1>;
			compatible = "allwinner,sun55iw6-r-pinctrl";
			reg = <0x0 0x07096000 0x0 0x800>;
#if 0
			interrupts = <GIC_SPI 202 IRQ_TYPE_LEVEL_HIGH>, /* GPIOL */
						 <GIC_SPI 204 IRQ_TYPE_LEVEL_HIGH>;     /* GPIOM */
#endif
			clocks = <&ccu CLK_R_APBS1>, <&dcxo24M>, <&rtc_ccu CLK_OSC32K>;
			clock-names = "apb", "hosc", "losc";
			gpio-controller;
			#gpio-cells = <3>;
			interrupt-controller;
			#interrupt-cells = <3>;
		};

		uart8: uart@2608000 {
			compatible = "allwinner,uart-v100";
			device_type = "uart8";
			reg = <0x0 0x02608000 0x0 0x400>;
			interrupts = <GIC_SPI 148 IRQ_TYPE_LEVEL_HIGH>;
			sunxi,uart-fifosize = <128>;
			clocks = <&ccu CLK_BUS_UART8>;
			resets = <&ccu RST_BUS_UART8>;
			uart8_port = <8>;
			uart8_type = <4>;
			//dmas = <&dma0 55>,<&dma0 55>;
			//dma-names = "tx","rx";
			status = "disabled";
		};


	};

	soc3: soc@3 {
		compatible = "simple-bus";
		#address-cells = <2>;
		#size-cells = <2>;
		ranges;
		device_type = "guest-soc";
		kylo-os-id = <3>;

		pio2: pinctrl@2 {
			//#address-cells = <1>;
			//#size-cells = <0>;
			compatible = "allwinner,sun55iw6-pinctrl";
			reg = <0x0 0x03604000 0x0 0x600>;
#if 0
			interrupts = <GIC_SPI 67 IRQ_TYPE_LEVEL_HIGH>,
							 <GIC_SPI 69 IRQ_TYPE_LEVEL_HIGH>,
							 <GIC_SPI 71 IRQ_TYPE_LEVEL_HIGH>,
							 <GIC_SPI 73 IRQ_TYPE_LEVEL_HIGH>,
							 <GIC_SPI 75 IRQ_TYPE_LEVEL_HIGH>,
							 <GIC_SPI 77 IRQ_TYPE_LEVEL_HIGH>,
							 <GIC_SPI 79 IRQ_TYPE_LEVEL_HIGH>,
							 <GIC_SPI 81 IRQ_TYPE_LEVEL_HIGH>,
							 <GIC_SPI 83 IRQ_TYPE_LEVEL_HIGH>,
							 <GIC_SPI 85 IRQ_TYPE_LEVEL_HIGH>,
							 <GIC_SPI 140 IRQ_TYPE_LEVEL_HIGH>;
#endif
			clocks = <&ccu CLK_APB1>, <&dcxo24M>, <&rtc_ccu CLK_OSC32K>;
			clock-names = "apb", "hosc", "losc";
			gpio-controller;
			#gpio-cells = <3>;
			interrupt-controller;
			#interrupt-cells = <3>;
		};

		r_pio2: pinctrl@22 {
			#address-cells = <1>;
			compatible = "allwinner,sun55iw6-r-pinctrl";
			reg = <0x0 0x07096000 0x0 0x800>;
#if 0
			interrupts = <GIC_SPI 202 IRQ_TYPE_LEVEL_HIGH>, /* GPIOL */
							<GIC_SPI 204 IRQ_TYPE_LEVEL_HIGH>;     /* GPIOM */
#endif
			clocks = <&ccu CLK_R_APBS1>, <&dcxo24M>, <&rtc_ccu CLK_OSC32K>;
			clock-names = "apb", "hosc", "losc";
			gpio-controller;
			#gpio-cells = <3>;
			interrupt-controller;
			#interrupt-cells = <3>;
		};

		uart2: uart@2602000 {
			compatible = "allwinner,uart-v100";
			device_type = "uart2";
			reg = <0x0 0x02602000 0x0 0x400>;
			interrupts = <GIC_SPI 4 IRQ_TYPE_LEVEL_HIGH>;
			sunxi,uart-fifosize = <128>;
			clocks = <&ccu CLK_BUS_UART2>;
			resets = <&ccu RST_BUS_UART2>;
			uart2_port = <2>;
			uart2_type = <4>;
			//dmas = <&dma0 16>,<&dma0 16>;
			//dma-names = "tx","rx";
			status = "disabled";
		};
	};


};

